[part 2 of 2: packages /Cluster to /Signal]
AUTOSAR XML (schema 00048)
package /Cluster  (continued)
  lin cluster LIN00: baudrate=19200, protocol-name=LIN, protocol-version=LIN21  # /*************************************************************************************/ // // Description: // Created: // Author: // Version: // Vehicle Project: // /*************************************************************************************/
    lin physical channel CHNL: comm-connectors=CN_LIN00
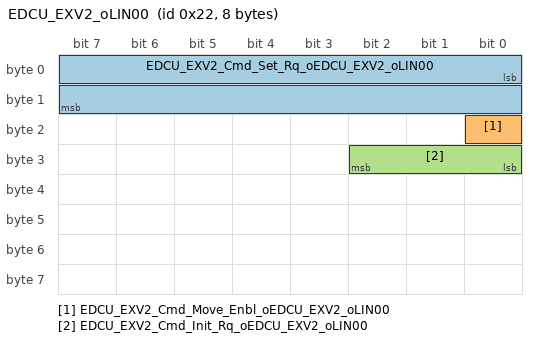
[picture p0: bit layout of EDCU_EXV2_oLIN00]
      frame EDCU_EXV2_oLIN00: id 0x22, from VCU, frame-length=8, lin-checksum=ENHANCED
        pdu EDCU_EXV2_oLIN00: length=8, unused-bit-pattern=255
          signal EDCU_EXV2_Cmd_Set_Rq_oEDCU_EXV2_oLIN00: start 0, 16 bit, little-endian, i-signal-type=PRIMITIVE, init-value=0, base-type=uint16, compu-method=CM_EDCU_EXV2_Cmd_Set_Rq, data-constr=DC_EDCU_EXV2_Cmd_Set_Rq
          signal EDCU_EXV2_Cmd_Move_Enbl_oEDCU_EXV2_oLIN00: start 16, 1 bit, little-endian, i-signal-type=PRIMITIVE, init-value=0, base-type=boolean, compu-method=CM_EDCU_EXV2_Cmd_Move_Enbl, data-constr=DC_EDCU_EXV2_Cmd_Move_Enbl
          signal EDCU_EXV2_Cmd_Init_Rq_oEDCU_EXV2_oLIN00: start 24, 3 bit, little-endian, i-signal-type=PRIMITIVE, init-value=0, base-type=uint8, compu-method=CM_EDCU_EXV2_Cmd_Init_Rq, data-constr=DC_EDCU_EXV2_Cmd_Init_Rq
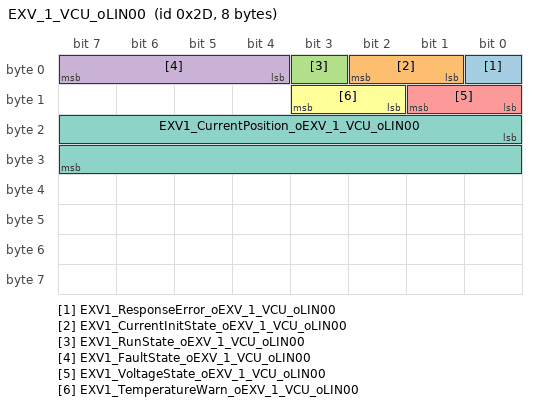
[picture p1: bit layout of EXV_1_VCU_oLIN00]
      frame EXV_1_VCU_oLIN00: id 0x2D, to VCU, frame-length=8, lin-checksum=ENHANCED
        pdu EXV_1_VCU_oLIN00: length=8, unused-bit-pattern=255
          signal EXV1_ResponseError_oEXV_1_VCU_oLIN00: start 0, 1 bit, little-endian, i-signal-type=PRIMITIVE, init-value=0, base-type=boolean, compu-method=CM_EXV1_ResponseError, data-constr=DC_EXV1_ResponseError, to VCU
          signal EXV1_CurrentInitState_oEXV_1_VCU_oLIN00: start 1, 2 bit, little-endian, i-signal-type=PRIMITIVE, init-value=0, base-type=uint8, compu-method=CM_EXV1_CurrentInitState, data-constr=DC_EXV1_CurrentInitState, to VCU
          signal EXV1_RunState_oEXV_1_VCU_oLIN00: start 3, 1 bit, little-endian, i-signal-type=PRIMITIVE, init-value=0, base-type=boolean, compu-method=CM_EXV1_RunState, data-constr=DC_EXV1_RunState, to VCU
          signal EXV1_FaultState_oEXV_1_VCU_oLIN00: start 4, 4 bit, little-endian, i-signal-type=PRIMITIVE, init-value=0, base-type=uint8, compu-method=CM_EXV1_FaultState, data-constr=DC_EXV1_FaultState, to VCU
          signal EXV1_VoltageState_oEXV_1_VCU_oLIN00: start 8, 2 bit, little-endian, i-signal-type=PRIMITIVE, init-value=0, base-type=uint8, compu-method=CM_EXV1_VoltageState, data-constr=DC_EXV1_VoltageState, to VCU
          signal EXV1_TemperatureWarn_oEXV_1_VCU_oLIN00: start 10, 2 bit, little-endian, i-signal-type=PRIMITIVE, init-value=0, base-type=uint8, compu-method=CM_EXV1_TemperatureWarn, data-constr=DC_EXV1_TemperatureWarn, to VCU
          signal EXV1_CurrentPosition_oEXV_1_VCU_oLIN00: start 16, 16 bit, little-endian, i-signal-type=PRIMITIVE, init-value=0, base-type=uint16, compu-method=CM_EXV1_CurrentPosition, data-constr=DC_EXV1_CurrentPosition, to VCU
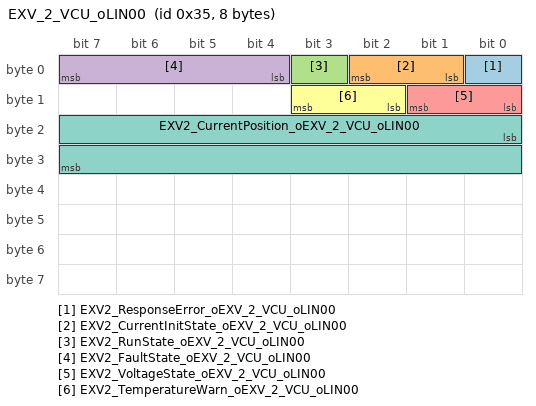
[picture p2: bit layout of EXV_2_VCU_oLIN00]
      frame EXV_2_VCU_oLIN00: id 0x35, to VCU, frame-length=8, lin-checksum=ENHANCED
        pdu EXV_2_VCU_oLIN00: length=8, unused-bit-pattern=255
          signal EXV2_ResponseError_oEXV_2_VCU_oLIN00: start 0, 1 bit, little-endian, i-signal-type=PRIMITIVE, init-value=0, base-type=boolean, compu-method=CM_EXV2_ResponseError, data-constr=DC_EXV2_ResponseError, to VCU
          signal EXV2_CurrentInitState_oEXV_2_VCU_oLIN00: start 1, 2 bit, little-endian, i-signal-type=PRIMITIVE, init-value=0, base-type=uint8, compu-method=CM_EXV2_CurrentInitState, data-constr=DC_EXV2_CurrentInitState, to VCU
          signal EXV2_RunState_oEXV_2_VCU_oLIN00: start 3, 1 bit, little-endian, i-signal-type=PRIMITIVE, init-value=0, base-type=boolean, compu-method=CM_EXV2_RunState, data-constr=DC_EXV2_RunState, to VCU
          signal EXV2_FaultState_oEXV_2_VCU_oLIN00: start 4, 4 bit, little-endian, i-signal-type=PRIMITIVE, init-value=0, base-type=uint8, compu-method=CM_EXV2_FaultState, data-constr=DC_EXV2_FaultState, to VCU
          signal EXV2_VoltageState_oEXV_2_VCU_oLIN00: start 8, 2 bit, little-endian, i-signal-type=PRIMITIVE, init-value=0, base-type=uint8, compu-method=CM_EXV2_VoltageState, data-constr=DC_EXV2_VoltageState, to VCU
          signal EXV2_TemperatureWarn_oEXV_2_VCU_oLIN00: start 10, 2 bit, little-endian, i-signal-type=PRIMITIVE, init-value=0, base-type=uint8, compu-method=CM_EXV2_TemperatureWarn, data-constr=DC_EXV2_TemperatureWarn, to VCU
          signal EXV2_CurrentPosition_oEXV_2_VCU_oLIN00: start 16, 16 bit, little-endian, i-signal-type=PRIMITIVE, init-value=0, base-type=uint16, compu-method=CM_EXV2_CurrentPosition, data-constr=DC_EXV2_CurrentPosition, to VCU
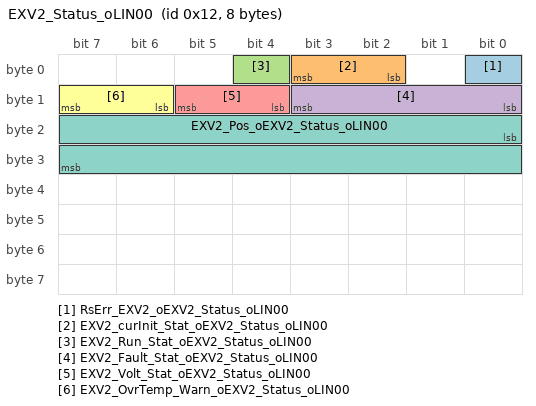
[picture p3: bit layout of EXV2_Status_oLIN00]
      frame EXV2_Status_oLIN00: id 0x12, to VCU, frame-length=8, lin-checksum=ENHANCED
        pdu EXV2_Status_oLIN00: length=8, unused-bit-pattern=255
          signal RsErr_EXV2_oEXV2_Status_oLIN00: start 0, 1 bit, little-endian, i-signal-type=PRIMITIVE, init-value=0, base-type=boolean, compu-method=CM_RsErr_EXV2, data-constr=DC_RsErr_EXV2, to VCU
          signal EXV2_curInit_Stat_oEXV2_Status_oLIN00: start 2, 2 bit, little-endian, i-signal-type=PRIMITIVE, init-value=0, base-type=uint8, compu-method=CM_EXV2_curInit_Stat, data-constr=DC_EXV2_curInit_Stat, to VCU
          signal EXV2_Run_Stat_oEXV2_Status_oLIN00: start 4, 1 bit, little-endian, i-signal-type=PRIMITIVE, init-value=0, base-type=boolean, compu-method=CM_EXV2_Run_Stat, data-constr=DC_EXV2_Run_Stat, to VCU
          signal EXV2_Fault_Stat_oEXV2_Status_oLIN00: start 8, 4 bit, little-endian, i-signal-type=PRIMITIVE, init-value=0, base-type=uint8, compu-method=CM_EXV2_Fault_Stat, data-constr=DC_EXV2_Fault_Stat, to VCU
          signal EXV2_Volt_Stat_oEXV2_Status_oLIN00: start 12, 2 bit, little-endian, i-signal-type=PRIMITIVE, init-value=0, base-type=uint8, compu-method=CM_EXV2_Volt_Stat, data-constr=DC_EXV2_Volt_Stat, to VCU
          signal EXV2_OvrTemp_Warn_oEXV2_Status_oLIN00: start 14, 2 bit, little-endian, i-signal-type=PRIMITIVE, init-value=0, base-type=uint8, compu-method=CM_EXV2_OvrTemp_Warn, data-constr=DC_EXV2_OvrTemp_Warn, to VCU
          signal EXV2_Pos_oEXV2_Status_oLIN00: start 16, 16 bit, little-endian, i-signal-type=PRIMITIVE, init-value=0, base-type=uint16, compu-method=CM_EXV2_Pos, data-constr=DC_EXV2_Pos, to VCU
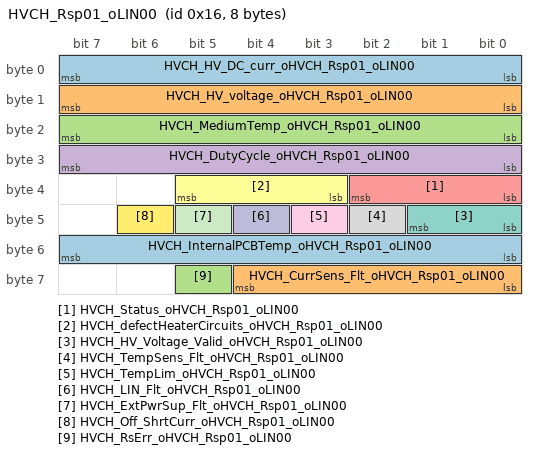
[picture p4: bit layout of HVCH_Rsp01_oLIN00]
      frame HVCH_Rsp01_oLIN00: id 0x16, to VCU, frame-length=8, lin-checksum=ENHANCED
        pdu HVCH_Rsp01_oLIN00: length=8, unused-bit-pattern=255
          signal HVCH_HV_DC_curr_oHVCH_Rsp01_oLIN00: start 0, 8 bit, little-endian, i-signal-type=PRIMITIVE, init-value=0, base-type=uint8, compu-method=CM_HVCH_HV_DC_curr, data-constr=DC_HVCH_HV_DC_curr, unit=U_A, to VCU
          signal HVCH_HV_voltage_oHVCH_Rsp01_oLIN00: start 8, 8 bit, little-endian, i-signal-type=PRIMITIVE, init-value=0, base-type=uint8, compu-method=CM_HVCH_HV_voltage, data-constr=DC_HVCH_HV_voltage, unit=U_V, to VCU
          signal HVCH_MediumTemp_oHVCH_Rsp01_oLIN00: start 16, 8 bit, little-endian, i-signal-type=PRIMITIVE, init-value=0, base-type=uint8, compu-method=CM_HVCH_MediumTemp, data-constr=DC_HVCH_MediumTemp, unit=U_celsius, to VCU
          signal HVCH_DutyCycle_oHVCH_Rsp01_oLIN00: start 24, 8 bit, little-endian, i-signal-type=PRIMITIVE, init-value=50, base-type=uint8, compu-method=CM_HVCH_DutyCycle, data-constr=DC_HVCH_DutyCycle, unit=U_percent, to VCU
          signal HVCH_Status_oHVCH_Rsp01_oLIN00: start 32, 3 bit, little-endian, i-signal-type=PRIMITIVE, init-value=0, base-type=uint8, compu-method=CM_HVCH_Status, data-constr=DC_HVCH_Status, to VCU
          signal HVCH_defectHeaterCircuits_oHVCH_Rsp01_oLIN00: start 35, 3 bit, little-endian, i-signal-type=PRIMITIVE, init-value=0, base-type=uint8, compu-method=CM_HVCH_defectHeaterCircuits, data-constr=DC_HVCH_defectHeaterCircuits, to VCU
          signal HVCH_HV_Voltage_Valid_oHVCH_Rsp01_oLIN00: start 40, 2 bit, little-endian, i-signal-type=PRIMITIVE, init-value=0, base-type=uint8, compu-method=CM_HVCH_HV_Voltage_Valid, data-constr=DC_HVCH_HV_Voltage_Valid, to VCU
          signal HVCH_TempSens_Flt_oHVCH_Rsp01_oLIN00: start 42, 1 bit, little-endian, i-signal-type=PRIMITIVE, init-value=0, base-type=boolean, compu-method=CM_HVCH_TempSens_Flt, data-constr=DC_HVCH_TempSens_Flt, to VCU
          signal HVCH_TempLim_oHVCH_Rsp01_oLIN00: start 43, 1 bit, little-endian, i-signal-type=PRIMITIVE, init-value=0, base-type=boolean, compu-method=CM_HVCH_TempLim, data-constr=DC_HVCH_TempLim, to VCU
          signal HVCH_LIN_Flt_oHVCH_Rsp01_oLIN00: start 44, 1 bit, little-endian, i-signal-type=PRIMITIVE, init-value=0, base-type=boolean, compu-method=CM_HVCH_LIN_Flt, data-constr=DC_HVCH_LIN_Flt, to VCU
          signal HVCH_ExtPwrSup_Flt_oHVCH_Rsp01_oLIN00: start 45, 1 bit, little-endian, i-signal-type=PRIMITIVE, init-value=0, base-type=boolean, compu-method=CM_HVCH_ExtPwrSup_Flt, data-constr=DC_HVCH_ExtPwrSup_Flt, to VCU
          signal HVCH_Off_ShrtCurr_oHVCH_Rsp01_oLIN00: start 46, 1 bit, little-endian, i-signal-type=PRIMITIVE, init-value=0, base-type=boolean, compu-method=CM_HVCH_Off_ShrtCurr, data-constr=DC_HVCH_Off_ShrtCurr, to VCU
          signal HVCH_InternalPCBTemp_oHVCH_Rsp01_oLIN00: start 48, 8 bit, little-endian, i-signal-type=PRIMITIVE, init-value=0, base-type=uint8, compu-method=CM_HVCH_InternalPCBTemp, data-constr=DC_HVCH_InternalPCBTemp, to VCU
          signal HVCH_CurrSens_Flt_oHVCH_Rsp01_oLIN00: start 56, 5 bit, little-endian, i-signal-type=PRIMITIVE, init-value=0, base-type=uint8, compu-method=CM_HVCH_CurrSens_Flt, data-constr=DC_HVCH_CurrSens_Flt, to VCU
          signal HVCH_RsErr_oHVCH_Rsp01_oLIN00: start 61, 1 bit, little-endian, i-signal-type=PRIMITIVE, init-value=0, base-type=boolean, compu-method=CM_HVCH_RsErr, data-constr=DC_HVCH_RsErr, to VCU
      frame HVCH_Rsp02_oLIN00: id 0x17, to VCU, frame-length=8, lin-checksum=ENHANCED
        pdu HVCH_Rsp02_oLIN00: length=8, unused-bit-pattern=255
          signal HVCH_IntelTemp_oHVCH_Rsp02_oLIN00: start 0, 8 bit, little-endian, i-signal-type=PRIMITIVE, init-value=0, base-type=uint8, compu-method=CM_HVCH_IntelTemp, data-constr=DC_HVCH_IntelTemp, unit=U_celsius, to VCU
      frame MasterReq_oLIN00: id 0x3C, from VCU, frame-length=8, lin-checksum=CLASSIC
        n pdu MasterReq_Tp_oLIN00: length=8
      frame PMP_Cmd_oLIN00: id 0x24, from VCU, frame-length=8, lin-checksum=ENHANCED
        pdu PMP_Cmd_oLIN00: length=8, unused-bit-pattern=255
          signal ECC_PMP2_SpdSet_oPMP_Cmd_oLIN00: start 8, 8 bit, little-endian, i-signal-type=PRIMITIVE, init-value=0, base-type=uint8, compu-method=CM_ECC_PMP2_SpdSet, data-constr=DC_ECC_PMP2_SpdSet, unit=U_p
          signal ECC_PMP3_SpdSet_oPMP_Cmd_oLIN00: start 16, 8 bit, little-endian, i-signal-type=PRIMITIVE, init-value=0, base-type=uint8, compu-method=CM_ECC_PMP3_SpdSet, data-constr=DC_ECC_PMP3_SpdSet, unit=U_p
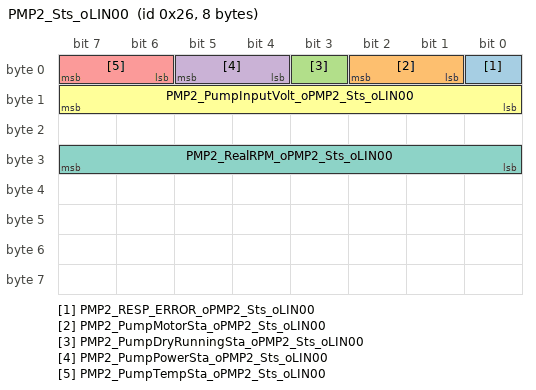
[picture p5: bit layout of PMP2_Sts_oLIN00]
      frame PMP2_Sts_oLIN00: id 0x26, to VCU, frame-length=8, lin-checksum=ENHANCED
        pdu PMP2_Sts_oLIN00: length=8, unused-bit-pattern=255
          signal PMP2_RESP_ERROR_oPMP2_Sts_oLIN00: start 0, 1 bit, little-endian, i-signal-type=PRIMITIVE, init-value=0, base-type=boolean, compu-method=CM_PMP2_RESP_ERROR, data-constr=DC_PMP2_RESP_ERROR, to VCU
          signal PMP2_PumpMotorSta_oPMP2_Sts_oLIN00: start 1, 2 bit, little-endian, i-signal-type=PRIMITIVE, init-value=0, base-type=uint8, compu-method=CM_PMP2_PumpMotorSta, data-constr=DC_PMP2_PumpMotorSta, to VCU
          signal PMP2_PumpDryRunningSta_oPMP2_Sts_oLIN00: start 3, 1 bit, little-endian, i-signal-type=PRIMITIVE, init-value=0, base-type=boolean, compu-method=CM_PMP2_PumpDryRunningSta, data-constr=DC_PMP2_PumpDryRunningSta, to VCU
          signal PMP2_PumpPowerSta_oPMP2_Sts_oLIN00: start 4, 2 bit, little-endian, i-signal-type=PRIMITIVE, init-value=0, base-type=uint8, compu-method=CM_PMP2_PumpPowerSta, data-constr=DC_PMP2_PumpPowerSta, to VCU
          signal PMP2_PumpTempSta_oPMP2_Sts_oLIN00: start 6, 2 bit, little-endian, i-signal-type=PRIMITIVE, init-value=0, base-type=uint8, compu-method=CM_PMP2_PumpTempSta, data-constr=DC_PMP2_PumpTempSta, to VCU
          signal PMP2_PumpInputVolt_oPMP2_Sts_oLIN00: start 8, 8 bit, little-endian, i-signal-type=PRIMITIVE, init-value=0, base-type=uint8, compu-method=CM_PMP2_PumpInputVolt, data-constr=DC_PMP2_PumpInputVolt, unit=U_V, to VCU
          signal PMP2_RealRPM_oPMP2_Sts_oLIN00: start 24, 8 bit, little-endian, i-signal-type=PRIMITIVE, init-value=0, base-type=uint8, compu-method=CM_PMP2_RealRPM, data-constr=DC_PMP2_RealRPM, unit=U_p, to VCU
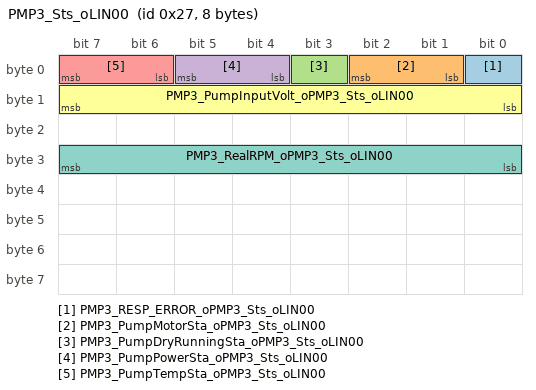
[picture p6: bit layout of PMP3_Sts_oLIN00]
      frame PMP3_Sts_oLIN00: id 0x27, to VCU, frame-length=8, lin-checksum=ENHANCED
        pdu PMP3_Sts_oLIN00: length=8, unused-bit-pattern=255
          signal PMP3_RESP_ERROR_oPMP3_Sts_oLIN00: start 0, 1 bit, little-endian, i-signal-type=PRIMITIVE, init-value=0, base-type=boolean, compu-method=CM_PMP3_RESP_ERROR, data-constr=DC_PMP3_RESP_ERROR, to VCU
          signal PMP3_PumpMotorSta_oPMP3_Sts_oLIN00: start 1, 2 bit, little-endian, i-signal-type=PRIMITIVE, init-value=0, base-type=uint8, compu-method=CM_PMP3_PumpMotorSta, data-constr=DC_PMP3_PumpMotorSta, to VCU
          signal PMP3_PumpDryRunningSta_oPMP3_Sts_oLIN00: start 3, 1 bit, little-endian, i-signal-type=PRIMITIVE, init-value=0, base-type=boolean, compu-method=CM_PMP3_PumpDryRunningSta, data-constr=DC_PMP3_PumpDryRunningSta, to VCU
          signal PMP3_PumpPowerSta_oPMP3_Sts_oLIN00: start 4, 2 bit, little-endian, i-signal-type=PRIMITIVE, init-value=0, base-type=uint8, compu-method=CM_PMP3_PumpPowerSta, data-constr=DC_PMP3_PumpPowerSta, to VCU
          signal PMP3_PumpTempSta_oPMP3_Sts_oLIN00: start 6, 2 bit, little-endian, i-signal-type=PRIMITIVE, init-value=0, base-type=uint8, compu-method=CM_PMP3_PumpTempSta, data-constr=DC_PMP3_PumpTempSta, to VCU
          signal PMP3_PumpInputVolt_oPMP3_Sts_oLIN00: start 8, 8 bit, little-endian, i-signal-type=PRIMITIVE, init-value=0, base-type=uint8, compu-method=CM_PMP3_PumpInputVolt, data-constr=DC_PMP3_PumpInputVolt, unit=U_V, to VCU
          signal PMP3_RealRPM_oPMP3_Sts_oLIN00: start 24, 8 bit, little-endian, i-signal-type=PRIMITIVE, init-value=0, base-type=uint8, compu-method=CM_PMP3_RealRPM, data-constr=DC_PMP3_RealRPM, unit=U_p, to VCU
      frame SlaveResp_oLIN00: id 0x3D, to VCU, frame-length=8, lin-checksum=CLASSIC
        n pdu SlaveResp_Tp_oLIN00: length=8
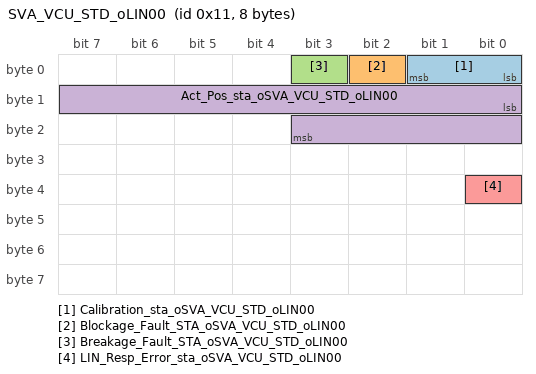
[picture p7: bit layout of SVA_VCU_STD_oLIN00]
      frame SVA_VCU_STD_oLIN00: id 0x11, to VCU, frame-length=8, lin-checksum=ENHANCED
        pdu SVA_VCU_STD_oLIN00: length=8, unused-bit-pattern=255
          signal Calibration_sta_oSVA_VCU_STD_oLIN00: start 0, 2 bit, little-endian, i-signal-type=PRIMITIVE, init-value=0, base-type=uint8, compu-method=CM_Calibration_sta, data-constr=DC_Calibration_sta, to VCU
          signal Blockage_Fault_STA_oSVA_VCU_STD_oLIN00: start 2, 1 bit, little-endian, i-signal-type=PRIMITIVE, init-value=0, base-type=boolean, compu-method=CM_Blockage_Fault_STA, data-constr=DC_Blockage_Fault_STA, to VCU
          signal Breakage_Fault_STA_oSVA_VCU_STD_oLIN00: start 3, 1 bit, little-endian, i-signal-type=PRIMITIVE, init-value=0, base-type=boolean, compu-method=CM_Breakage_Fault_STA, data-constr=DC_Breakage_Fault_STA, to VCU
          signal Act_Pos_sta_oSVA_VCU_STD_oLIN00: start 8, 12 bit, little-endian, i-signal-type=PRIMITIVE, init-value=0, base-type=uint16, compu-method=CM_Act_Pos_sta, data-constr=DC_Act_Pos_sta, unit=U_Degree, to VCU
          signal LIN_Resp_Error_sta_oSVA_VCU_STD_oLIN00: start 32, 1 bit, little-endian, i-signal-type=PRIMITIVE, init-value=0, base-type=boolean, compu-method=CM_LIN_Resp_Error_sta, data-constr=DC_LIN_Resp_Error_sta, to VCU
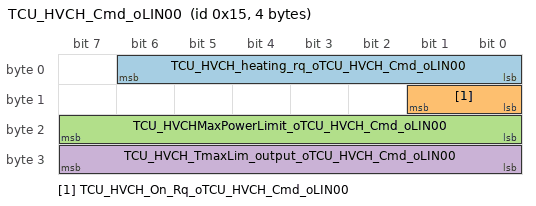
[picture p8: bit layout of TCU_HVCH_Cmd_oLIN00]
      frame TCU_HVCH_Cmd_oLIN00: id 0x15, from VCU, frame-length=4, lin-checksum=ENHANCED
        pdu TCU_HVCH_Cmd_oLIN00: length=4, unused-bit-pattern=255
          signal TCU_HVCH_heating_rq_oTCU_HVCH_Cmd_oLIN00: start 0, 7 bit, little-endian, i-signal-type=PRIMITIVE, init-value=0, base-type=uint8, compu-method=CM_TCU_HVCH_heating_rq, data-constr=DC_TCU_HVCH_heating_rq, unit=U_percent
          signal TCU_HVCH_On_Rq_oTCU_HVCH_Cmd_oLIN00: start 8, 2 bit, little-endian, i-signal-type=PRIMITIVE, init-value=0, base-type=uint8, invalid-value=3, compu-method=CM_TCU_HVCH_On_Rq, data-constr=DC_TCU_HVCH_On_Rq
          signal TCU_HVCHMaxPowerLimit_oTCU_HVCH_Cmd_oLIN00: start 16, 8 bit, little-endian, i-signal-type=PRIMITIVE, init-value=0, base-type=uint8, compu-method=CM_TCU_HVCHMaxPowerLimit, data-constr=DC_TCU_HVCHMaxPowerLimit, unit=U_KW
          signal TCU_HVCH_TmaxLim_output_oTCU_HVCH_Cmd_oLIN00: start 24, 8 bit, little-endian, i-signal-type=PRIMITIVE, init-value=0, base-type=uint8, compu-method=CM_TCU_HVCH_TmaxLim_output, data-constr=DC_TCU_HVCH_TmaxLim_output, unit=U_celsius
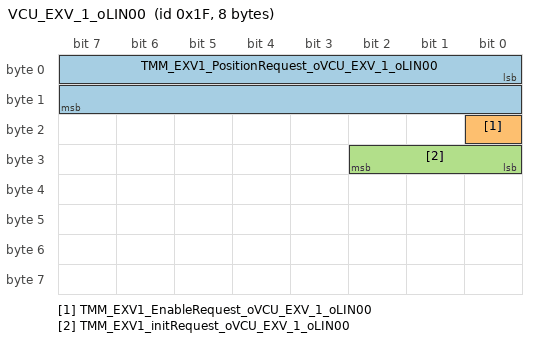
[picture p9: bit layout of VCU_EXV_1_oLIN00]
      frame VCU_EXV_1_oLIN00: id 0x1F, from VCU, frame-length=8, lin-checksum=ENHANCED
        pdu VCU_EXV_1_oLIN00: length=8, unused-bit-pattern=255
          signal TMM_EXV1_PositionRequest_oVCU_EXV_1_oLIN00: start 0, 16 bit, little-endian, i-signal-type=PRIMITIVE, init-value=0, base-type=uint16, compu-method=CM_TMM_EXV1_PositionRequest, data-constr=DC_TMM_EXV1_PositionRequest
          signal TMM_EXV1_EnableRequest_oVCU_EXV_1_oLIN00: start 16, 1 bit, little-endian, i-signal-type=PRIMITIVE, init-value=0, base-type=boolean, compu-method=CM_TMM_EXV1_EnableRequest, data-constr=DC_TMM_EXV1_EnableRequest
          signal TMM_EXV1_initRequest_oVCU_EXV_1_oLIN00: start 24, 3 bit, little-endian, i-signal-type=PRIMITIVE, init-value=0, base-type=uint8, compu-method=CM_TMM_EXV1_initRequest, data-constr=DC_TMM_EXV1_initRequest
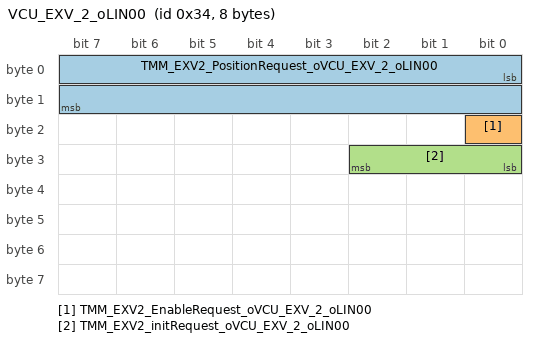
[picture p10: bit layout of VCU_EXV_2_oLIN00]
      frame VCU_EXV_2_oLIN00: id 0x34, from VCU, frame-length=8, lin-checksum=ENHANCED
        pdu VCU_EXV_2_oLIN00: length=8, unused-bit-pattern=255
          signal TMM_EXV2_PositionRequest_oVCU_EXV_2_oLIN00: start 0, 16 bit, little-endian, i-signal-type=PRIMITIVE, init-value=0, base-type=uint16, compu-method=CM_TMM_EXV2_PositionRequest, data-constr=DC_TMM_EXV2_PositionRequest
          signal TMM_EXV2_EnableRequest_oVCU_EXV_2_oLIN00: start 16, 1 bit, little-endian, i-signal-type=PRIMITIVE, init-value=0, base-type=boolean, compu-method=CM_TMM_EXV2_EnableRequest, data-constr=DC_TMM_EXV2_EnableRequest
          signal TMM_EXV2_initRequest_oVCU_EXV_2_oLIN00: start 24, 3 bit, little-endian, i-signal-type=PRIMITIVE, init-value=0, base-type=uint8, compu-method=CM_TMM_EXV2_initRequest, data-constr=DC_TMM_EXV2_initRequest
      frame VCU_SVA_CMD_oLIN00: id 0x10, from VCU, frame-length=8, lin-checksum=ENHANCED
        pdu VCU_SVA_CMD_oLIN00: length=8, unused-bit-pattern=255
          signal Calibration_cmd_oVCU_SVA_CMD_oLIN00: start 8, 1 bit, little-endian, i-signal-type=PRIMITIVE, init-value=0, base-type=boolean, compu-method=CM_Calibration_cmd, data-constr=DC_Calibration_cmd
          signal Target_Pos_cmd_oVCU_SVA_CMD_oLIN00: start 16, 12 bit, little-endian, i-signal-type=PRIMITIVE, init-value=0, base-type=uint16, compu-method=CM_Target_Pos_cmd, data-constr=DC_Target_Pos_cmd, unit=U_Degree
      pdu triggering PT_MasterReq: pdu=MasterReq_oLIN00, from VCU
      pdu triggering PT_MasterReq_ERV: pdu=MasterReq_ERV_oLIN00, from VCU
      pdu triggering PT_MasterReq_EXV_1: pdu=MasterReq_EXV_1_oLIN00, from VCU
      pdu triggering PT_MasterReq_EXV_2: pdu=MasterReq_EXV_2_oLIN00, from VCU
      pdu triggering PT_MasterReq_HVCH: pdu=MasterReq_HVCH_oLIN00, from VCU
      pdu triggering PT_MasterReq_PMP_1: pdu=MasterReq_PMP_1_oLIN00, from VCU
      pdu triggering PT_MasterReq_PMP_2: pdu=MasterReq_PMP_2_oLIN00, from VCU
      pdu triggering PT_MasterReq_SVA: pdu=MasterReq_SVA_oLIN00, from VCU
      pdu triggering PT_SlaveResp_ERV: pdu=SlaveResp_ERV_oLIN00, to VCU
      pdu triggering PT_SlaveResp_EXV_1: pdu=SlaveResp_EXV_1_oLIN00, to VCU
      pdu triggering PT_SlaveResp_EXV_2: pdu=SlaveResp_EXV_2_oLIN00, to VCU
      pdu triggering PT_SlaveResp_HVCH: pdu=SlaveResp_HVCH_oLIN00, to VCU
      pdu triggering PT_SlaveResp_PMP_1: pdu=SlaveResp_PMP_1_oLIN00, to VCU
      pdu triggering PT_SlaveResp_PMP_2: pdu=SlaveResp_PMP_2_oLIN00, to VCU
      pdu triggering PT_SlaveResp_SVA: pdu=SlaveResp_SVA_oLIN00, to VCU
      lin schedule table TCU_LIN_Schedule: run-mode=RUN-CONTINUOUS
        table-entrys:
          delay=0.01, position-in-table=0, frame-triggering=FT_EDCU_EXV2
          delay=0.01, position-in-table=1, frame-triggering=FT_EXV2_Status
          delay=0.1, position-in-table=2, frame-triggering=FT_VCU_EXV_1
          delay=0.1, position-in-table=3, frame-triggering=FT_EXV_1_VCU
          delay=0.1, position-in-table=4, frame-triggering=FT_VCU_EXV_2
          delay=0.1, position-in-table=5, frame-triggering=FT_EXV_2_VCU
          delay=0.01, position-in-table=6, frame-triggering=FT_PMP_Cmd
          delay=0.01, position-in-table=7, frame-triggering=FT_PMP2_Sts
          delay=0.01, position-in-table=8, frame-triggering=FT_PMP3_Sts
          delay=0.015, position-in-table=9, frame-triggering=FT_VCU_SVA_CMD
          delay=0.015, position-in-table=10, frame-triggering=FT_SVA_VCU_STD
          delay=0.02, position-in-table=11, frame-triggering=FT_TCU_HVCH_Cmd
          delay=0.02, position-in-table=12, frame-triggering=FT_HVCH_Rsp01
          delay=0.02, position-in-table=13, frame-triggering=FT_HVCH_Rsp02
  lin cluster LIN01: baudrate=19200, protocol-name=LIN, protocol-version=LIN21  # LIN4 | /*************************************************************************************/ // // Description: // Created: // Author: // Version: // Vehicle Project: // /*************************************************************************************/
    lin physical channel CHNL: comm-connectors=CN_LIN01
      frame MasterReq_oLIN01: id 0x3C, from VCU, frame-length=8, lin-checksum=CLASSIC
        n pdu MasterReq_Tp_oLIN01: length=8
      frame SlaveResp_oLIN01: id 0x3D, to VCU, frame-length=8, lin-checksum=CLASSIC
        n pdu SlaveResp_Tp_oLIN01: length=8
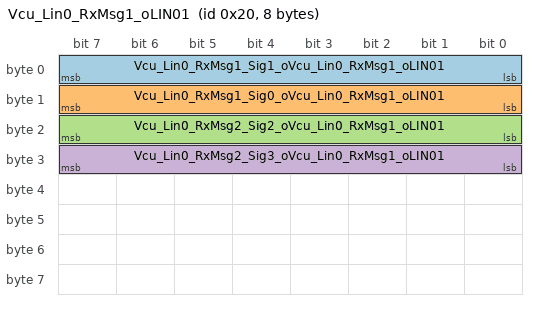
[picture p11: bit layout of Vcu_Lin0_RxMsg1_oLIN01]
      frame Vcu_Lin0_RxMsg1_oLIN01: id 0x20, to VCU, frame-length=8, lin-checksum=ENHANCED
        pdu Vcu_Lin0_RxMsg1_oLIN01: length=8, unused-bit-pattern=255
          signal Vcu_Lin0_RxMsg1_Sig1_oVcu_Lin0_RxMsg1_oLIN01: start 0, 8 bit, little-endian, i-signal-type=PRIMITIVE, init-value=0, base-type=uint8, compu-method=CM_Vcu_Lin0_RxMsg1_Sig1, data-constr=DC_Vcu_Lin0_RxMsg1_Sig1, to VCU
          signal Vcu_Lin0_RxMsg1_Sig0_oVcu_Lin0_RxMsg1_oLIN01: start 8, 8 bit, little-endian, i-signal-type=PRIMITIVE, init-value=0, base-type=uint8, compu-method=CM_Vcu_Lin0_RxMsg1_Sig0, data-constr=DC_Vcu_Lin0_RxMsg1_Sig0, to VCU
          signal Vcu_Lin0_RxMsg2_Sig2_oVcu_Lin0_RxMsg1_oLIN01: start 16, 8 bit, little-endian, i-signal-type=PRIMITIVE, init-value=0, base-type=uint8, compu-method=CM_Vcu_Lin0_RxMsg2_Sig2, data-constr=DC_Vcu_Lin0_RxMsg2_Sig2, to VCU
          signal Vcu_Lin0_RxMsg2_Sig3_oVcu_Lin0_RxMsg1_oLIN01: start 24, 8 bit, little-endian, i-signal-type=PRIMITIVE, init-value=0, base-type=uint8, compu-method=CM_Vcu_Lin0_RxMsg2_Sig3, data-constr=DC_Vcu_Lin0_RxMsg2_Sig3, to VCU
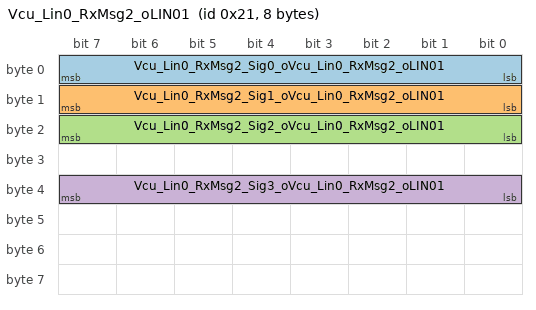
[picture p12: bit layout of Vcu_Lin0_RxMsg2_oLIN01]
      frame Vcu_Lin0_RxMsg2_oLIN01: id 0x21, to VCU, frame-length=8, lin-checksum=ENHANCED
        pdu Vcu_Lin0_RxMsg2_oLIN01: length=8, unused-bit-pattern=255
          signal Vcu_Lin0_RxMsg2_Sig0_oVcu_Lin0_RxMsg2_oLIN01: start 0, 8 bit, little-endian, i-signal-type=PRIMITIVE, init-value=0, base-type=uint8, compu-method=CM_Vcu_Lin0_RxMsg2_Sig0, data-constr=DC_Vcu_Lin0_RxMsg2_Sig0, to VCU
          signal Vcu_Lin0_RxMsg2_Sig1_oVcu_Lin0_RxMsg2_oLIN01: start 8, 8 bit, little-endian, i-signal-type=PRIMITIVE, init-value=0, base-type=uint8, compu-method=CM_Vcu_Lin0_RxMsg2_Sig1, data-constr=DC_Vcu_Lin0_RxMsg2_Sig1, to VCU
          signal Vcu_Lin0_RxMsg2_Sig2_oVcu_Lin0_RxMsg2_oLIN01: start 16, 8 bit, little-endian, i-signal-type=PRIMITIVE, init-value=0, base-type=uint8, compu-method=CM_Vcu_Lin0_RxMsg2_Sig2, data-constr=DC_Vcu_Lin0_RxMsg2_Sig2, to VCU
          signal Vcu_Lin0_RxMsg2_Sig3_oVcu_Lin0_RxMsg2_oLIN01: start 32, 8 bit, little-endian, i-signal-type=PRIMITIVE, init-value=0, base-type=uint8, compu-method=CM_Vcu_Lin0_RxMsg2_Sig3, data-constr=DC_Vcu_Lin0_RxMsg2_Sig3, to VCU
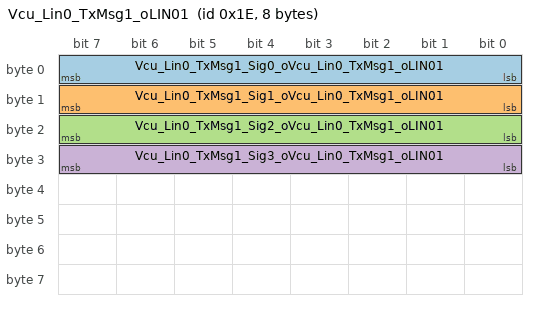
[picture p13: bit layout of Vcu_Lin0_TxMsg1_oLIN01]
      frame Vcu_Lin0_TxMsg1_oLIN01: id 0x1E, from VCU, frame-length=8, lin-checksum=ENHANCED
        pdu Vcu_Lin0_TxMsg1_oLIN01: length=8, unused-bit-pattern=255
          signal Vcu_Lin0_TxMsg1_Sig0_oVcu_Lin0_TxMsg1_oLIN01: start 0, 8 bit, little-endian, i-signal-type=PRIMITIVE, init-value=0, base-type=uint8, compu-method=CM_Vcu_Lin0_TxMsg1_Sig0, data-constr=DC_Vcu_Lin0_TxMsg1_Sig0
          signal Vcu_Lin0_TxMsg1_Sig1_oVcu_Lin0_TxMsg1_oLIN01: start 8, 8 bit, little-endian, i-signal-type=PRIMITIVE, init-value=0, base-type=uint8, compu-method=CM_Vcu_Lin0_TxMsg1_Sig1, data-constr=DC_Vcu_Lin0_TxMsg1_Sig1
          signal Vcu_Lin0_TxMsg1_Sig2_oVcu_Lin0_TxMsg1_oLIN01: start 16, 8 bit, little-endian, i-signal-type=PRIMITIVE, init-value=0, base-type=uint8, compu-method=CM_Vcu_Lin0_TxMsg1_Sig2, data-constr=DC_Vcu_Lin0_TxMsg1_Sig2
          signal Vcu_Lin0_TxMsg1_Sig3_oVcu_Lin0_TxMsg1_oLIN01: start 24, 8 bit, little-endian, i-signal-type=PRIMITIVE, init-value=0, base-type=uint8, compu-method=CM_Vcu_Lin0_TxMsg1_Sig3, data-constr=DC_Vcu_Lin0_TxMsg1_Sig3
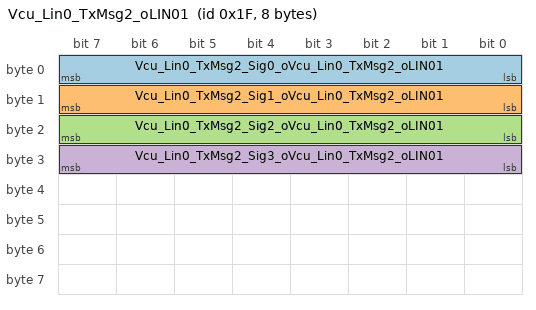
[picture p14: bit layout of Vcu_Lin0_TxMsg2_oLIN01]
      frame Vcu_Lin0_TxMsg2_oLIN01: id 0x1F, from VCU, frame-length=8, lin-checksum=ENHANCED
        pdu Vcu_Lin0_TxMsg2_oLIN01: length=8, unused-bit-pattern=255
          signal Vcu_Lin0_TxMsg2_Sig0_oVcu_Lin0_TxMsg2_oLIN01: start 0, 8 bit, little-endian, i-signal-type=PRIMITIVE, init-value=0, base-type=uint8, compu-method=CM_Vcu_Lin0_TxMsg2_Sig0, data-constr=DC_Vcu_Lin0_TxMsg2_Sig0
          signal Vcu_Lin0_TxMsg2_Sig1_oVcu_Lin0_TxMsg2_oLIN01: start 8, 8 bit, little-endian, i-signal-type=PRIMITIVE, init-value=0, base-type=uint8, compu-method=CM_Vcu_Lin0_TxMsg2_Sig1, data-constr=DC_Vcu_Lin0_TxMsg2_Sig1
          signal Vcu_Lin0_TxMsg2_Sig2_oVcu_Lin0_TxMsg2_oLIN01: start 16, 8 bit, little-endian, i-signal-type=PRIMITIVE, init-value=0, base-type=uint8, compu-method=CM_Vcu_Lin0_TxMsg2_Sig2, data-constr=DC_Vcu_Lin0_TxMsg2_Sig2
          signal Vcu_Lin0_TxMsg2_Sig3_oVcu_Lin0_TxMsg2_oLIN01: start 24, 8 bit, little-endian, i-signal-type=PRIMITIVE, init-value=0, base-type=uint8, compu-method=CM_Vcu_Lin0_TxMsg2_Sig3, data-constr=DC_Vcu_Lin0_TxMsg2_Sig3
      pdu triggering PT_MasterReq: pdu=MasterReq_oLIN01, from VCU
      pdu triggering PT_MasterReq_GWM: pdu=MasterReq_GWM_oLIN01, from VCU
      pdu triggering PT_SlaveResp_GWM: pdu=SlaveResp_GWM_oLIN01, to VCU
      lin schedule table Vcu_Lin0_Schedule: run-mode=RUN-CONTINUOUS
        table-entrys:
          delay=0.02, position-in-table=0, frame-triggering=FT_Vcu_Lin0_TxMsg1
          delay=0.02, position-in-table=1, frame-triggering=FT_Vcu_Lin0_TxMsg2
          delay=0.02, position-in-table=2, frame-triggering=FT_Vcu_Lin0_RxMsg1
          delay=0.02, position-in-table=3, frame-triggering=FT_Vcu_Lin0_RxMsg2
  lin cluster LIN02: baudrate=19200, protocol-name=LIN, protocol-version=LIN21  # LIN3 | /*************************************************************************************/ // // Description: // Created: // Author: // Version: // Vehicle Project: // /*************************************************************************************/
    lin physical channel CHNL: comm-connectors=CN_LIN02
      frame MasterReq_oLIN02: id 0x3C, from VCU, frame-length=8, lin-checksum=CLASSIC
        n pdu MasterReq_Tp_oLIN02: length=8
      frame SlaveResp_oLIN02: id 0x3D, to VCU, frame-length=8, lin-checksum=CLASSIC
        n pdu SlaveResp_Tp_oLIN02: length=8
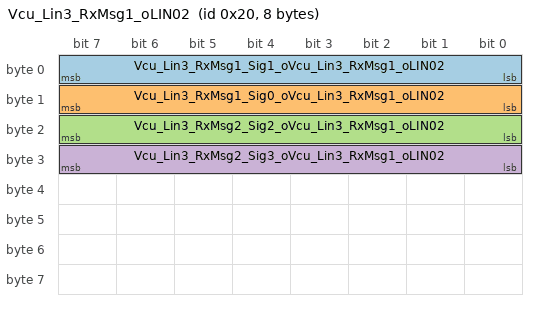
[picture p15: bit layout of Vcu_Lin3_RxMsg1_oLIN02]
      frame Vcu_Lin3_RxMsg1_oLIN02: id 0x20, to VCU, frame-length=8, lin-checksum=ENHANCED
        pdu Vcu_Lin3_RxMsg1_oLIN02: length=8, unused-bit-pattern=255
          signal Vcu_Lin3_RxMsg1_Sig1_oVcu_Lin3_RxMsg1_oLIN02: start 0, 8 bit, little-endian, i-signal-type=PRIMITIVE, init-value=0, base-type=uint8, compu-method=CM_Vcu_Lin3_RxMsg1_Sig1, data-constr=DC_Vcu_Lin3_RxMsg1_Sig1, to VCU
          signal Vcu_Lin3_RxMsg1_Sig0_oVcu_Lin3_RxMsg1_oLIN02: start 8, 8 bit, little-endian, i-signal-type=PRIMITIVE, init-value=0, base-type=uint8, compu-method=CM_Vcu_Lin3_RxMsg1_Sig0, data-constr=DC_Vcu_Lin3_RxMsg1_Sig0, to VCU
          signal Vcu_Lin3_RxMsg2_Sig2_oVcu_Lin3_RxMsg1_oLIN02: start 16, 8 bit, little-endian, i-signal-type=PRIMITIVE, init-value=0, base-type=uint8, compu-method=CM_Vcu_Lin3_RxMsg2_Sig2, data-constr=DC_Vcu_Lin3_RxMsg2_Sig2, to VCU
          signal Vcu_Lin3_RxMsg2_Sig3_oVcu_Lin3_RxMsg1_oLIN02: start 24, 8 bit, little-endian, i-signal-type=PRIMITIVE, init-value=0, base-type=uint8, compu-method=CM_Vcu_Lin3_RxMsg2_Sig3, data-constr=DC_Vcu_Lin3_RxMsg2_Sig3, to VCU
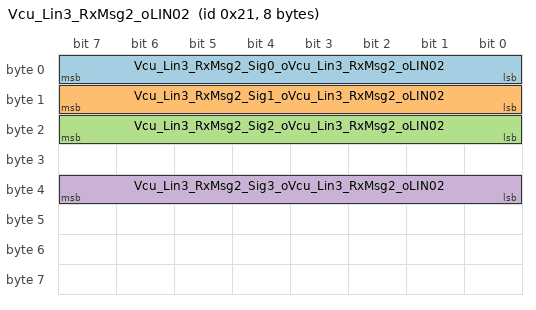
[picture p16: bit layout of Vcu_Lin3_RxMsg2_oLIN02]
      frame Vcu_Lin3_RxMsg2_oLIN02: id 0x21, to VCU, frame-length=8, lin-checksum=ENHANCED
        pdu Vcu_Lin3_RxMsg2_oLIN02: length=8, unused-bit-pattern=255
          signal Vcu_Lin3_RxMsg2_Sig0_oVcu_Lin3_RxMsg2_oLIN02: start 0, 8 bit, little-endian, i-signal-type=PRIMITIVE, init-value=0, base-type=uint8, compu-method=CM_Vcu_Lin3_RxMsg2_Sig0, data-constr=DC_Vcu_Lin3_RxMsg2_Sig0, to VCU
          signal Vcu_Lin3_RxMsg2_Sig1_oVcu_Lin3_RxMsg2_oLIN02: start 8, 8 bit, little-endian, i-signal-type=PRIMITIVE, init-value=0, base-type=uint8, compu-method=CM_Vcu_Lin3_RxMsg2_Sig1, data-constr=DC_Vcu_Lin3_RxMsg2_Sig1, to VCU
          signal Vcu_Lin3_RxMsg2_Sig2_oVcu_Lin3_RxMsg2_oLIN02: start 16, 8 bit, little-endian, i-signal-type=PRIMITIVE, init-value=0, base-type=uint8, compu-method=CM_Vcu_Lin3_RxMsg2_Sig2, data-constr=DC_Vcu_Lin3_RxMsg2_Sig2, to VCU
          signal Vcu_Lin3_RxMsg2_Sig3_oVcu_Lin3_RxMsg2_oLIN02: start 32, 8 bit, little-endian, i-signal-type=PRIMITIVE, init-value=0, base-type=uint8, compu-method=CM_Vcu_Lin3_RxMsg2_Sig3, data-constr=DC_Vcu_Lin3_RxMsg2_Sig3, to VCU
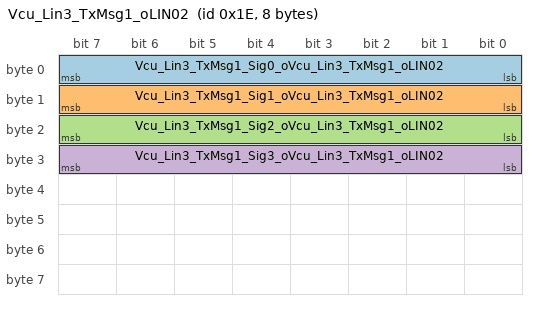
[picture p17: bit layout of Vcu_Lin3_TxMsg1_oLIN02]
      frame Vcu_Lin3_TxMsg1_oLIN02: id 0x1E, from VCU, frame-length=8, lin-checksum=ENHANCED
        pdu Vcu_Lin3_TxMsg1_oLIN02: length=8, unused-bit-pattern=255
          signal Vcu_Lin3_TxMsg1_Sig0_oVcu_Lin3_TxMsg1_oLIN02: start 0, 8 bit, little-endian, i-signal-type=PRIMITIVE, init-value=0, base-type=uint8, compu-method=CM_Vcu_Lin3_TxMsg1_Sig0, data-constr=DC_Vcu_Lin3_TxMsg1_Sig0
          signal Vcu_Lin3_TxMsg1_Sig1_oVcu_Lin3_TxMsg1_oLIN02: start 8, 8 bit, little-endian, i-signal-type=PRIMITIVE, init-value=0, base-type=uint8, compu-method=CM_Vcu_Lin3_TxMsg1_Sig1, data-constr=DC_Vcu_Lin3_TxMsg1_Sig1
          signal Vcu_Lin3_TxMsg1_Sig2_oVcu_Lin3_TxMsg1_oLIN02: start 16, 8 bit, little-endian, i-signal-type=PRIMITIVE, init-value=0, base-type=uint8, compu-method=CM_Vcu_Lin3_TxMsg1_Sig2, data-constr=DC_Vcu_Lin3_TxMsg1_Sig2
          signal Vcu_Lin3_TxMsg1_Sig3_oVcu_Lin3_TxMsg1_oLIN02: start 24, 8 bit, little-endian, i-signal-type=PRIMITIVE, init-value=0, base-type=uint8, compu-method=CM_Vcu_Lin3_TxMsg1_Sig3, data-constr=DC_Vcu_Lin3_TxMsg1_Sig3
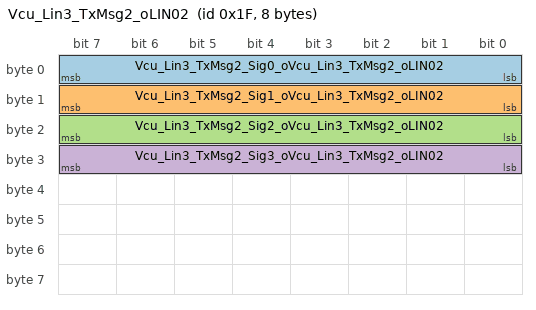
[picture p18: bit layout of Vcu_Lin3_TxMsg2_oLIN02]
      frame Vcu_Lin3_TxMsg2_oLIN02: id 0x1F, from VCU, frame-length=8, lin-checksum=ENHANCED
        pdu Vcu_Lin3_TxMsg2_oLIN02: length=8, unused-bit-pattern=255
          signal Vcu_Lin3_TxMsg2_Sig0_oVcu_Lin3_TxMsg2_oLIN02: start 0, 8 bit, little-endian, i-signal-type=PRIMITIVE, init-value=0, base-type=uint8, compu-method=CM_Vcu_Lin3_TxMsg2_Sig0, data-constr=DC_Vcu_Lin3_TxMsg2_Sig0
          signal Vcu_Lin3_TxMsg2_Sig1_oVcu_Lin3_TxMsg2_oLIN02: start 8, 8 bit, little-endian, i-signal-type=PRIMITIVE, init-value=0, base-type=uint8, compu-method=CM_Vcu_Lin3_TxMsg2_Sig1, data-constr=DC_Vcu_Lin3_TxMsg2_Sig1
          signal Vcu_Lin3_TxMsg2_Sig2_oVcu_Lin3_TxMsg2_oLIN02: start 16, 8 bit, little-endian, i-signal-type=PRIMITIVE, init-value=0, base-type=uint8, compu-method=CM_Vcu_Lin3_TxMsg2_Sig2, data-constr=DC_Vcu_Lin3_TxMsg2_Sig2
          signal Vcu_Lin3_TxMsg2_Sig3_oVcu_Lin3_TxMsg2_oLIN02: start 24, 8 bit, little-endian, i-signal-type=PRIMITIVE, init-value=0, base-type=uint8, compu-method=CM_Vcu_Lin3_TxMsg2_Sig3, data-constr=DC_Vcu_Lin3_TxMsg2_Sig3
      pdu triggering PT_MasterReq: pdu=MasterReq_oLIN02, from VCU
      pdu triggering PT_MasterReq_GWM: pdu=MasterReq_GWM_oLIN02, from VCU
      pdu triggering PT_SlaveResp_GWM: pdu=SlaveResp_GWM_oLIN02, to VCU
      lin schedule table Vcu_Lin3_Schedule: run-mode=RUN-CONTINUOUS
        table-entrys:
          delay=0.02, position-in-table=0, frame-triggering=FT_Vcu_Lin3_TxMsg1
          delay=0.02, position-in-table=1, frame-triggering=FT_Vcu_Lin3_TxMsg2
          delay=0.02, position-in-table=2, frame-triggering=FT_Vcu_Lin3_RxMsg1
          delay=0.02, position-in-table=3, frame-triggering=FT_Vcu_Lin3_RxMsg2
package /ECU
  ecu instance VCU: associated-com-i-pdu-group=[VCU_oATOM_CANFD_Matrix_CH_V600_202502_Rx, VCU_oATOM_CANFD_Matrix_CH_V600_202502_Tx, VCU_oLIN00_Rx, VCU_oLIN00_Tx, VCU_oLIN01_Rx, VCU_oLIN01_Tx, VCU_oLIN02_Rx, VCU_oLIN02_Tx, VCU_oTC37X_VCU_CAN00_Rx, VCU_oTC37X_VCU_CAN00_Tx, VCU_oTC37X_VCU_CAN01_Rx, VCU_oTC37X_VCU_CAN01_Tx, VCU_oTC37X_VCU_CAN03_Rx, VCU_oTC37X_VCU_CAN03_Tx, VCU_oTC37X_VCU_CAN12_Rx, VCU_oTC37X_VCU_CAN12_Tx]
    5 x can communication controller:
      CT_ATOM_CANFD_Matrix_CH_V600_202502
      CT_TC37X_VCU_CAN00
      CT_TC37X_VCU_CAN01
      CT_TC37X_VCU_CAN03
      CT_TC37X_VCU_CAN12
    lin master CT_LIN{00..02}: protocol-version=LIN21, time-base=0.005, time-base-jitter=0.0001
    can communication connector CN_ATOM_CANFD_Matrix_CH_V600_202502: comm-controller=CT_ATOM_CANFD_Matrix_CH_V600_202502
    can communication connector CN_TC37X_VCU_CAN00: comm-controller=CT_TC37X_VCU_CAN00
    can communication connector CN_TC37X_VCU_CAN01: comm-controller=CT_TC37X_VCU_CAN01
    can communication connector CN_TC37X_VCU_CAN03: comm-controller=CT_TC37X_VCU_CAN03
    can communication connector CN_TC37X_VCU_CAN12: comm-controller=CT_TC37X_VCU_CAN12
    lin communication connector CN_LIN{00..02}: comm-controller=CT_LIN{00..02}
package /Gateway
  gateway VCU: ecu=VCU
package /IPDUGroup
  16 x i signal i pdu group:
    VCU_oATOM_CANFD_Matrix_CH_V600_202502_Rx: communication-direction=IN
      i-signal-i-pdus:
        ACU_01_oATOM_CANFD_Matrix_CH_V600_202502
        ACU_02_oATOM_CANFD_Matrix_CH_V600_202502
        ACU_info_oATOM_CANFD_Matrix_CH_V600_202502
        ADCU_ACC_02_oATOM_CANFD_Matrix_CH_V600_202502
        ADCU_AEB_01_oATOM_CANFD_Matrix_CH_V600_202502
        ADCU_APS_01_oATOM_CANFD_Matrix_CH_V600_202502
        ADCU_APS_02_oATOM_CANFD_Matrix_CH_V600_202502
        ADCU_DA_oATOM_CANFD_Matrix_CH_V600_202502
        IBS_ACC_oATOM_CANFD_Matrix_CH_V600_202502
        IBS_APS_oATOM_CANFD_Matrix_CH_V600_202502
        IBS_Status_{01..04}_oATOM_CANFD_Matrix_CH_V600_202502
        IBS_Status_06_oATOM_CANFD_Matrix_CH_V600_202502
        IBS_Torque_oATOM_CANFD_Matrix_CH_V600_202502
        IBS_VCU_MotorControl_oATOM_CANFD_Matrix_CH_V600_202502
        IBS_WheelSpeed_01_oATOM_CANFD_Matrix_CH_V600_202502
        IBS_WheelSpeed_02_oATOM_CANFD_Matrix_CH_V600_202502
        SGW_17_oATOM_CANFD_Matrix_CH_V600_202502
    VCU_oATOM_CANFD_Matrix_CH_V600_202502_Tx: communication-direction=OUT
      i-signal-i-pdus:
        VCU_{02..04}_oATOM_CANFD_Matrix_CH_V600_202502
        VCU_AccPedal_oATOM_CANFD_Matrix_CH_V600_202502
        VCU_BMS_oATOM_CANFD_Matrix_CH_V600_202502
        VCU_Chassis_01_oATOM_CANFD_Matrix_CH_V600_202502
        VCU_HMIsignals_01_oATOM_CANFD_Matrix_CH_V600_202502
        VCU_HMIsignals_02_oATOM_CANFD_Matrix_CH_V600_202502
        VCU_IBS_01_oATOM_CANFD_Matrix_CH_V600_202502
        VCU_MCU_03_oATOM_CANFD_Matrix_CH_V600_202502
        VCU_PlugInChrgInfo_oATOM_CANFD_Matrix_CH_V600_202502
    VCU_oLIN00_Rx: communication-direction=IN
      i-signal-i-pdus:
        EXV_1_VCU_oLIN00
        EXV_2_VCU_oLIN00
        EXV2_Status_oLIN00
        HVCH_Rsp01_oLIN00
        HVCH_Rsp02_oLIN00
        PMP2_Sts_oLIN00
        PMP3_Sts_oLIN00
        SVA_VCU_STD_oLIN00
    VCU_oLIN00_Tx: communication-direction=OUT, i-signal-i-pdus=[EDCU_EXV2_oLIN00, PMP_Cmd_oLIN00, TCU_HVCH_Cmd_oLIN00, VCU_EXV_1_oLIN00, VCU_EXV_2_oLIN00, VCU_SVA_CMD_oLIN00]
    VCU_oLIN01_Rx: communication-direction=IN, i-signal-i-pdus=[Vcu_Lin0_RxMsg1_oLIN01, Vcu_Lin0_RxMsg2_oLIN01]
    VCU_oLIN01_Tx: communication-direction=OUT, i-signal-i-pdus=[Vcu_Lin0_TxMsg1_oLIN01, Vcu_Lin0_TxMsg2_oLIN01]
    VCU_oLIN02_Rx: communication-direction=IN, i-signal-i-pdus=[Vcu_Lin3_RxMsg1_oLIN02, Vcu_Lin3_RxMsg2_oLIN02]
    VCU_oLIN02_Tx: communication-direction=OUT, i-signal-i-pdus=[Vcu_Lin3_TxMsg1_oLIN02, Vcu_Lin3_TxMsg2_oLIN02]
    VCU_oTC37X_VCU_CAN00_Rx: communication-direction=IN, i-signal-i-pdus=[VcuRxMsg1_oTC37X_VCU_CAN00, VcuRxMsg2_oTC37X_VCU_CAN00]
    VCU_oTC37X_VCU_CAN00_Tx: communication-direction=OUT
      i-signal-i-pdus:
        VcuTxIoMsg{1..8}_oTC37X_VCU_CAN00
        VcuTxMsg1_oTC37X_VCU_CAN00
        VcuTxMsg2_oTC37X_VCU_CAN00
    VCU_oTC37X_VCU_CAN01_Rx: communication-direction=IN
      i-signal-i-pdus:
        VcuRxCtrlMsg{0..2}_oTC37X_VCU_CAN01
        VcuRxMsg3_oTC37X_VCU_CAN01
        VcuRxMsg4_oTC37X_VCU_CAN01
    VCU_oTC37X_VCU_CAN01_Tx: communication-direction=OUT
      i-signal-i-pdus:
        VcuAdcTxG0Msg0_oTC37X_VCU_CAN01
        VcuAdcTxG0Msg1_oTC37X_VCU_CAN01
        VcuAdcTxG1Msg0_oTC37X_VCU_CAN01
        VcuAdcTxG1Msg1_oTC37X_VCU_CAN01
        VcuAdcTxG2Msg0_oTC37X_VCU_CAN01
        VcuAdcTxG2Msg1_oTC37X_VCU_CAN01
        VcuAdcTxG3Msg0_oTC37X_VCU_CAN01
        VcuAdcTxG3Msg1_oTC37X_VCU_CAN01
        VcuAdcTxG8Msg{0..3}_oTC37X_VCU_CAN01
        VcuMeasurementMsg0_oTC37X_VCU_CAN01
    VCU_oTC37X_VCU_CAN03_Rx: communication-direction=IN, i-signal-i-pdus=[VcuCan03RxMsg1_oTC37X_VCU_CAN03, VcuCan03RxMsg2_oTC37X_VCU_CAN03]
    VCU_oTC37X_VCU_CAN03_Tx: communication-direction=OUT, i-signal-i-pdus=[VcuCan03TxMsg1_oTC37X_VCU_CAN03, VcuCan03TxMsg2_oTC37X_VCU_CAN03]
    VCU_oTC37X_VCU_CAN12_Rx: communication-direction=IN, i-signal-i-pdus=[VcuCan12RxMsg3_oTC37X_VCU_CAN12, VcuCan12RxMsg4_oTC37X_VCU_CAN12]
    VCU_oTC37X_VCU_CAN12_Tx: communication-direction=OUT, i-signal-i-pdus=[VcuCan12TxMsg1_oTC37X_VCU_CAN12, VcuCan12TxMsg2_oTC37X_VCU_CAN12]
package /PDU
  dcm i pdu MasterReq_ERV_oLIN00: length=8, diag-pdu-type=DIAG-REQUEST
  dcm i pdu MasterReq_EXV_1_oLIN00: length=8, diag-pdu-type=DIAG-REQUEST
  dcm i pdu MasterReq_EXV_2_oLIN00: length=8, diag-pdu-type=DIAG-REQUEST
  dcm i pdu MasterReq_GWM_oLIN01: length=8, diag-pdu-type=DIAG-REQUEST
  dcm i pdu MasterReq_GWM_oLIN02: length=8, diag-pdu-type=DIAG-REQUEST
  dcm i pdu MasterReq_HVCH_oLIN00: length=8, diag-pdu-type=DIAG-REQUEST
  dcm i pdu MasterReq_oLIN{00..02}: length=8, diag-pdu-type=DIAG-REQUEST
  dcm i pdu MasterReq_PMP_1_oLIN00: length=8, diag-pdu-type=DIAG-REQUEST
  dcm i pdu MasterReq_PMP_2_oLIN00: length=8, diag-pdu-type=DIAG-REQUEST
  dcm i pdu MasterReq_SVA_oLIN00: length=8, diag-pdu-type=DIAG-REQUEST
  dcm i pdu SlaveResp_ERV_oLIN00: length=8, diag-pdu-type=DIAG-RESPONSE
  dcm i pdu SlaveResp_EXV_1_oLIN00: length=8, diag-pdu-type=DIAG-RESPONSE
  dcm i pdu SlaveResp_EXV_2_oLIN00: length=8, diag-pdu-type=DIAG-RESPONSE
  dcm i pdu SlaveResp_GWM_oLIN01: length=8, diag-pdu-type=DIAG-RESPONSE
  dcm i pdu SlaveResp_GWM_oLIN02: length=8, diag-pdu-type=DIAG-RESPONSE
  dcm i pdu SlaveResp_HVCH_oLIN00: length=8, diag-pdu-type=DIAG-RESPONSE
  dcm i pdu SlaveResp_PMP_1_oLIN00: length=8, diag-pdu-type=DIAG-RESPONSE
  dcm i pdu SlaveResp_PMP_2_oLIN00: length=8, diag-pdu-type=DIAG-RESPONSE
  dcm i pdu SlaveResp_SVA_oLIN00: length=8, diag-pdu-type=DIAG-RESPONSE
  dcm i pdu Vcu_Uds_Func_Request_oTC37X_VCU_CAN00: length=7, diag-pdu-type=DIAG-REQUEST
  dcm i pdu Vcu_Uds_Phy_Request_oTC37X_VCU_CAN00: length=8, diag-pdu-type=DIAG-REQUEST
  dcm i pdu Vcu_Uds_Response_oTC37X_VCU_CAN00: length=8, diag-pdu-type=DIAG-RESPONSE
package /ISignal
  31 x i signal group:
    SG_ACU_01_SigGroup_oACU_01_oATOM_CANFD_Matrix_CH_V600_202502: i-signal=[ACU_YawRate_oACU_01_oATOM_CANFD_Matrix_CH_V600_202502, ACU_YawRateStatus_oACU_01_oATOM_CANFD_Matrix_CH_V600_202502, Checksum_0F5_oACU_01_oATOM_CANFD_Matrix_CH_V600_202502, MessageCounter_0F5_oACU_01_oATOM_CANFD_Matrix_CH_V600_202502], system-signal-group=SG_ACU_01_SigGroup
    SG_ACU_02_SigGroup_oACU_02_oATOM_CANFD_Matrix_CH_V600_202502: i-signal=[ACU_LatA_oACU_02_oATOM_CANFD_Matrix_CH_V600_202502, ACU_LatAStatus_oACU_02_oATOM_CANFD_Matrix_CH_V600_202502, ACU_LgtA_oACU_02_oATOM_CANFD_Matrix_CH_V600_202502, ACU_LgtAStatus_oACU_02_oATOM_CANFD_Matrix_CH_V600_202502, Checksum_0F6_oACU_02_oATOM_CANFD_Matrix_CH_V600_202502, MessageCounter_0F6_oACU_02_oATOM_CANFD_Matrix_CH_V600_202502], system-signal-group=SG_ACU_02_SigGroup
    SG_ACU_info_SigGroup_oACU_info_oATOM_CANFD_Matrix_CH_V600_202502: i-signal=[ACU_CrashOutputSts_oACU_info_oATOM_CANFD_Matrix_CH_V600_202502, ACU_CrashOutputStsValid_oACU_info_oATOM_CANFD_Matrix_CH_V600_202502, ACU_DriverSeatBeltSts_oACU_info_oATOM_CANFD_Matrix_CH_V600_202502, ACU_DriverSeatBeltStsValid_oACU_info_oATOM_CANFD_Matrix_CH_V600_202502, ACU_DriverWarningLampSts_oACU_info_oATOM_CANFD_Matrix_CH_V600_202502, ACU_PassengerAirbagSts_oACU_info_oATOM_CANFD_Matrix_CH_V600_202502, ACU_PassengerSeatBeltSts_oACU_info_oATOM_CANFD_Matrix_CH_V600_202502, ACU_PassengerSeatBeltStsValid_oACU_info_oATOM_CANFD_Matrix_CH_V600_202502, ACU_PassengerSts_oACU_info_oATOM_CANFD_Matrix_CH_V600_202502, ACU_PassengerWarningLampSts_oACU_info_oATOM_CANFD_Matrix_CH_V600_202502, ACU_RLSeatBeltStatusValid_oACU_info_oATOM_CANFD_Matrix_CH_V600_202502, ACU_RRSeatBeltStatusValid_oACU_info_oATOM_CANFD_Matrix_CH_V600_202502, ACU_SecondLeftSeatBeltSts_oACU_info_oATOM_CANFD_Matrix_CH_V600_202502, ACU_SecondLeftSts_oACU_info_oATOM_CANFD_Matrix_CH_V600_202502, ACU_SecondRightSeatBeltSts_oACU_info_oATOM_CANFD_Matrix_CH_V600_202502, ACU_SecondRightSts_oACU_info_oATOM_CANFD_Matrix_CH_V600_202502, ACU_WarningLampSts_oACU_info_oATOM_CANFD_Matrix_CH_V600_202502, Checksum_097_oACU_info_oATOM_CANFD_Matrix_CH_V600_202502, MessageCounter_097_oACU_info_oATOM_CANFD_Matrix_CH_V600_202502], system-signal-group=SG_ACU_info_SigGroup
    SG_ADCU_ACC_02_SigGroup_oADCU_ACC_02_oATOM_CANFD_Matrix_CH_V600_202502: i-signal=[ADCU_ACC_Mode_oADCU_ACC_02_oATOM_CANFD_Matrix_CH_V600_202502, ADCU_ACCDA_HandsOFF_Warning_oADCU_ACC_02_oATOM_CANFD_Matrix_CH_V600_202502, ADCU_ACCDA_SYS_Failure_oADCU_ACC_02_oATOM_CANFD_Matrix_CH_V600_202502, Checksum_0E0_oADCU_ACC_02_oATOM_CANFD_Matrix_CH_V600_202502, MessageCounter_0E0_oADCU_ACC_02_oATOM_CANFD_Matrix_CH_V600_202502], system-signal-group=SG_ADCU_ACC_02_SigGroup
    SG_ADCU_AEB_01_SigGroup_oADCU_AEB_01_oATOM_CANFD_Matrix_CH_V600_202502: i-signal=[ADCU_AEB_AWB_Level_oADCU_AEB_01_oATOM_CANFD_Matrix_CH_V600_202502, ADCU_AEB_AWB_Req_oADCU_AEB_01_oATOM_CANFD_Matrix_CH_V600_202502, ADCU_AEB_Decel_Cmd_oADCU_AEB_01_oATOM_CANFD_Matrix_CH_V600_202502, ADCU_AEB_Prefill_CMD_oADCU_AEB_01_oATOM_CANFD_Matrix_CH_V600_202502, ADCU_AEB_State_oADCU_AEB_01_oATOM_CANFD_Matrix_CH_V600_202502, ADCU_AEB_Stop_Req_oADCU_AEB_01_oATOM_CANFD_Matrix_CH_V600_202502, ADCU_AEBReq_oADCU_AEB_01_oATOM_CANFD_Matrix_CH_V600_202502, ADCU_AEBWarningSts_oADCU_AEB_01_oATOM_CANFD_Matrix_CH_V600_202502, ADCU_FCW_State_oADCU_AEB_01_oATOM_CANFD_Matrix_CH_V600_202502, Checksum_0E2_oADCU_AEB_01_oATOM_CANFD_Matrix_CH_V600_202502, MessageCounter_0E2_oADCU_AEB_01_oATOM_CANFD_Matrix_CH_V600_202502], system-signal-group=SG_ADCU_AEB_01_SigGroup
    SG_ADCU_APS_01_SigGroup_oADCU_APS_01_oATOM_CANFD_Matrix_CH_V600_202502: i-signal=[ADCU_APS_Stop_Req_oADCU_APS_01_oATOM_CANFD_Matrix_CH_V600_202502, ADCU_APSComfBrkReq_oADCU_APS_01_oATOM_CANFD_Matrix_CH_V600_202502, ADCU_APSCrlModeReq_oADCU_APS_01_oATOM_CANFD_Matrix_CH_V600_202502, ADCU_APSCrlReq_oADCU_APS_01_oATOM_CANFD_Matrix_CH_V600_202502, ADCU_APSCrlTypReq_oADCU_APS_01_oATOM_CANFD_Matrix_CH_V600_202502, ADCU_APSDistanceStop_oADCU_APS_01_oATOM_CANFD_Matrix_CH_V600_202502, ADCU_APSMaxSpeedReq_oADCU_APS_01_oATOM_CANFD_Matrix_CH_V600_202502, ADCU_Parking_CtrlSts_oADCU_APS_01_oATOM_CANFD_Matrix_CH_V600_202502, ADCU_Parking_Mode_oADCU_APS_01_oATOM_CANFD_Matrix_CH_V600_202502, ADCU_TargetGear_oADCU_APS_01_oATOM_CANFD_Matrix_CH_V600_202502, Checksum_0E4_oADCU_APS_01_oATOM_CANFD_Matrix_CH_V600_202502, MessageCounter_0E4_oADCU_APS_01_oATOM_CANFD_Matrix_CH_V600_202502], system-signal-group=SG_ADCU_APS_01_SigGroup
    SG_ADCU_APS_02_SigGroup_oADCU_APS_02_oATOM_CANFD_Matrix_CH_V600_202502: i-signal=ADCU_RemoteParkingMode_oADCU_APS_02_oATOM_CANFD_Matrix_CH_V600_202502, system-signal-group=SG_ADCU_APS_02_SigGroup
    SG_ADCU_DA_SigGroup_oADCU_DA_oATOM_CANFD_Matrix_CH_V600_202502: i-signal=[ADCU_DA_Mode_oADCU_DA_oATOM_CANFD_Matrix_CH_V600_202502, Checksum_0E6_oADCU_DA_oATOM_CANFD_Matrix_CH_V600_202502, MessageCounter_0E6_oADCU_DA_oATOM_CANFD_Matrix_CH_V600_202502], system-signal-group=SG_ADCU_DA_SigGroup
    SG_IBS_ACC_SigGroup_oIBS_ACC_oATOM_CANFD_Matrix_CH_V600_202502: i-signal=[Checksum_0B8_oIBS_ACC_oATOM_CANFD_Matrix_CH_V600_202502, IBS_CddActive_oIBS_ACC_oATOM_CANFD_Matrix_CH_V600_202502, IBS_CddAvailable_oIBS_ACC_oATOM_CANFD_Matrix_CH_V600_202502, IBS_CddError_oIBS_ACC_oATOM_CANFD_Matrix_CH_V600_202502, IBS_VehicleStandstill_oIBS_ACC_oATOM_CANFD_Matrix_CH_V600_202502, IBS_VehicleStandstill_Valid_oIBS_ACC_oATOM_CANFD_Matrix_CH_V600_202502, IBS_VlcActive_oIBS_ACC_oATOM_CANFD_Matrix_CH_V600_202502, IBS_VlcAvalible_oIBS_ACC_oATOM_CANFD_Matrix_CH_V600_202502, IBS_VlcError_oIBS_ACC_oATOM_CANFD_Matrix_CH_V600_202502, IBS_WLTorqueVLCReq_oIBS_ACC_oATOM_CANFD_Matrix_CH_V600_202502, IBS_WLTorqueVLCReqValid_oIBS_ACC_oATOM_CANFD_Matrix_CH_V600_202502, MessageCounter_0B8_oIBS_ACC_oATOM_CANFD_Matrix_CH_V600_202502], system-signal-group=SG_IBS_ACC_SigGroup
    SG_IBS_APS_SigGroup_oIBS_APS_oATOM_CANFD_Matrix_CH_V600_202502: i-signal=[Checksum_0B7_oIBS_APS_oATOM_CANFD_Matrix_CH_V600_202502, IBS_APS_Avl_oIBS_APS_oATOM_CANFD_Matrix_CH_V600_202502, IBS_APSComfortAvl_oIBS_APS_oATOM_CANFD_Matrix_CH_V600_202502, IBS_APSCrlReqEcho_oIBS_APS_oATOM_CANFD_Matrix_CH_V600_202502, IBS_APSEmergenyAvl_oIBS_APS_oATOM_CANFD_Matrix_CH_V600_202502, IBS_APSModeEcho_oIBS_APS_oATOM_CANFD_Matrix_CH_V600_202502, IBS_APSTrqReqActive_oIBS_APS_oATOM_CANFD_Matrix_CH_V600_202502, IBS_BrakeTypEcho_oIBS_APS_oATOM_CANFD_Matrix_CH_V600_202502, MessageCounter_0B7_oIBS_APS_oATOM_CANFD_Matrix_CH_V600_202502], system-signal-group=SG_IBS_APS_SigGroup
    SG_IBS_Status_01_SigGroup_oIBS_Status_01_oATOM_CANFD_Matrix_CH_V600_202502: i-signal=[Checksum_0B2_oIBS_Status_01_oATOM_CANFD_Matrix_CH_V600_202502, IBS_BrakePedalStatus_oIBS_Status_01_oATOM_CANFD_Matrix_CH_V600_202502, IBS_BrakePedalStatusValid_oIBS_Status_01_oATOM_CANFD_Matrix_CH_V600_202502, IBS_BrakePushrodStroke_oIBS_Status_01_oATOM_CANFD_Matrix_CH_V600_202502, IBS_MasterCylinderPressure_oIBS_Status_01_oATOM_CANFD_Matrix_CH_V600_202502, IBS_PlungerPressure_oIBS_Status_01_oATOM_CANFD_Matrix_CH_V600_202502, MessageCounter_0B2_oIBS_Status_01_oATOM_CANFD_Matrix_CH_V600_202502], system-signal-group=SG_IBS_Status_01_SigGroup
    SG_IBS_Status_02_SigGroup_oIBS_Status_02_oATOM_CANFD_Matrix_CH_V600_202502: i-signal=[Checksum_0B3_oIBS_Status_02_oATOM_CANFD_Matrix_CH_V600_202502, IBS_AEBActive_oIBS_Status_02_oATOM_CANFD_Matrix_CH_V600_202502, IBS_AEBAvailable_oIBS_Status_02_oATOM_CANFD_Matrix_CH_V600_202502, IBS_AVHAvailable_oIBS_Status_02_oATOM_CANFD_Matrix_CH_V600_202502, IBS_AWBActive_oIBS_Status_02_oATOM_CANFD_Matrix_CH_V600_202502, IBS_AWBAvailable_oIBS_Status_02_oATOM_CANFD_Matrix_CH_V600_202502, IBS_BrakeLightRequest_oIBS_Status_02_oATOM_CANFD_Matrix_CH_V600_202502, IBS_EPBControllerSts_oIBS_Status_02_oATOM_CANFD_Matrix_CH_V600_202502, IBS_EPBFailureLamp_oIBS_Status_02_oATOM_CANFD_Matrix_CH_V600_202502, IBS_EPBFunctionLamp_oIBS_Status_02_oATOM_CANFD_Matrix_CH_V600_202502, IBS_EPBworkingSts_oIBS_Status_02_oATOM_CANFD_Matrix_CH_V600_202502, IBS_HazWarnReq_oIBS_Status_02_oATOM_CANFD_Matrix_CH_V600_202502, IBS_HDCAvailable_oIBS_Status_02_oATOM_CANFD_Matrix_CH_V600_202502, IBS_HHCActive_oIBS_Status_02_oATOM_CANFD_Matrix_CH_V600_202502, IBS_HHCAvailable_oIBS_Status_02_oATOM_CANFD_Matrix_CH_V600_202502, IBS_TCSActive_oIBS_Status_02_oATOM_CANFD_Matrix_CH_V600_202502, IBS_VDCActive_oIBS_Status_02_oATOM_CANFD_Matrix_CH_V600_202502, MessageCounter_0B3_oIBS_Status_02_oATOM_CANFD_Matrix_CH_V600_202502], system-signal-group=SG_IBS_Status_02_SigGroup
    SG_IBS_Status_03_SigGroup_oIBS_Status_03_oATOM_CANFD_Matrix_CH_V600_202502: i-signal=[Checksum_0B4_oIBS_Status_03_oATOM_CANFD_Matrix_CH_V600_202502, IBS_ABPActive_oIBS_Status_03_oATOM_CANFD_Matrix_CH_V600_202502, IBS_ABPAvailable_oIBS_Status_03_oATOM_CANFD_Matrix_CH_V600_202502, IBS_ABSActive_oIBS_Status_03_oATOM_CANFD_Matrix_CH_V600_202502, IBS_ABSFault_oIBS_Status_03_oATOM_CANFD_Matrix_CH_V600_202502, IBS_DTCFault_oIBS_Status_03_oATOM_CANFD_Matrix_CH_V600_202502, IBS_EBDActive_oIBS_Status_03_oATOM_CANFD_Matrix_CH_V600_202502, IBS_EBDFault_oIBS_Status_03_oATOM_CANFD_Matrix_CH_V600_202502, IBS_EPBTextdisplay_oIBS_Status_03_oATOM_CANFD_Matrix_CH_V600_202502, IBS_SystemStatus_oIBS_Status_03_oATOM_CANFD_Matrix_CH_V600_202502, IBS_TCSFault_oIBS_Status_03_oATOM_CANFD_Matrix_CH_V600_202502, IBS_VCU_DecelerationRequest_Available_oIBS_Status_03_oATOM_CANFD_Matrix_CH_V600_202502, IBS_VDCFault_oIBS_Status_03_oATOM_CANFD_Matrix_CH_V600_202502, IBS_VehicleSpeed_oIBS_Status_03_oATOM_CANFD_Matrix_CH_V600_202502, IBS_VehicleSpeedValid_oIBS_Status_03_oATOM_CANFD_Matrix_CH_V600_202502, MessageCounter_0B4_oIBS_Status_03_oATOM_CANFD_Matrix_CH_V600_202502], system-signal-group=SG_IBS_Status_03_SigGroup
    SG_IBS_Status_04_SigGroup_oIBS_Status_04_oATOM_CANFD_Matrix_CH_V600_202502: i-signal=[Checksum_0BA_oIBS_Status_04_oATOM_CANFD_Matrix_CH_V600_202502, IBS_CDPActive_oIBS_Status_04_oATOM_CANFD_Matrix_CH_V600_202502, IBS_CDPAvailable_oIBS_Status_04_oATOM_CANFD_Matrix_CH_V600_202502, IBS_DTCActive_oIBS_Status_04_oATOM_CANFD_Matrix_CH_V600_202502, MessageCounter_0BA_oIBS_Status_04_oATOM_CANFD_Matrix_CH_V600_202502], system-signal-group=SG_IBS_Status_04_SigGroup
    SG_IBS_Status_06_SigGroup_oIBS_Status_06_oATOM_CANFD_Matrix_CH_V600_202502: i-signal=[Checksum_0BC_oIBS_Status_06_oATOM_CANFD_Matrix_CH_V600_202502, IBS_AVHSts_oIBS_Status_06_oATOM_CANFD_Matrix_CH_V600_202502, IBS_BrakeFluidWarning_oIBS_Status_06_oATOM_CANFD_Matrix_CH_V600_202502, IBS_EPBFailureStatus_oIBS_Status_06_oATOM_CANFD_Matrix_CH_V600_202502, IBS_ESClampdisplay_oIBS_Status_06_oATOM_CANFD_Matrix_CH_V600_202502, IBS_ESCOffSts_oIBS_Status_06_oATOM_CANFD_Matrix_CH_V600_202502, IBS_FactoryMode_oIBS_Status_06_oATOM_CANFD_Matrix_CH_V600_202502, IBS_HBAActive_oIBS_Status_06_oATOM_CANFD_Matrix_CH_V600_202502, IBS_HDCSts_oIBS_Status_06_oATOM_CANFD_Matrix_CH_V600_202502, IBS_MaintenaceMode_oIBS_Status_06_oATOM_CANFD_Matrix_CH_V600_202502, IBS_RollerbenchMode_oIBS_Status_06_oATOM_CANFD_Matrix_CH_V600_202502, IBS_RWUActive_oIBS_Status_06_oATOM_CANFD_Matrix_CH_V600_202502, IBS_RWUAvailable_oIBS_Status_06_oATOM_CANFD_Matrix_CH_V600_202502, IBS_TireMonSysSts_oIBS_Status_06_oATOM_CANFD_Matrix_CH_V600_202502, IBS_TireWarnFrntLe_oIBS_Status_06_oATOM_CANFD_Matrix_CH_V600_202502, IBS_TireWarnFrntRi_oIBS_Status_06_oATOM_CANFD_Matrix_CH_V600_202502, IBS_TireWarnReLe_oIBS_Status_06_oATOM_CANFD_Matrix_CH_V600_202502, IBS_TireWarnReRi_oIBS_Status_06_oATOM_CANFD_Matrix_CH_V600_202502, IBS_TPMS_ResetSts_oIBS_Status_06_oATOM_CANFD_Matrix_CH_V600_202502, MessageCounter_0BC_oIBS_Status_06_oATOM_CANFD_Matrix_CH_V600_202502], system-signal-group=SG_IBS_Status_06_SigGroup
    SG_IBS_Torque_SigGroup_oIBS_Torque_oATOM_CANFD_Matrix_CH_V600_202502: i-signal=[Checksum_0B9_oIBS_Torque_oATOM_CANFD_Matrix_CH_V600_202502, IBS_RBSStatus_oIBS_Torque_oATOM_CANFD_Matrix_CH_V600_202502, IBS_TargetGearReq_oIBS_Torque_oATOM_CANFD_Matrix_CH_V600_202502, IBS_VCU_DecelerationReqActive_oIBS_Torque_oATOM_CANFD_Matrix_CH_V600_202502, IBS_WLTorqueAPSReq_oIBS_Torque_oATOM_CANFD_Matrix_CH_V600_202502, IBS_WLTorqueAPSReqValid_oIBS_Torque_oATOM_CANFD_Matrix_CH_V600_202502, IBS_WLTorqueRBSReq_oIBS_Torque_oATOM_CANFD_Matrix_CH_V600_202502, IBS_WLTorqueRBSReqValid_oIBS_Torque_oATOM_CANFD_Matrix_CH_V600_202502, MessageCounter_0B9_oIBS_Torque_oATOM_CANFD_Matrix_CH_V600_202502], system-signal-group=SG_IBS_Torque_SigGroup
    SG_IBS_VCU_MotorControl_SigGroup_oIBS_VCU_MotorControl_oATOM_CANFD_Matrix_CH_V600_202502: i-signal=[Checksum_090_oIBS_VCU_MotorControl_oATOM_CANFD_Matrix_CH_V600_202502, IBS_WLTorqueIncrReq_oIBS_VCU_MotorControl_oATOM_CANFD_Matrix_CH_V600_202502, IBS_WLTorqueIncrReqSts_oIBS_VCU_MotorControl_oATOM_CANFD_Matrix_CH_V600_202502, IBS_WLTorqueRedReq_oIBS_VCU_MotorControl_oATOM_CANFD_Matrix_CH_V600_202502, IBS_WLTorqueRedReqSts_oIBS_VCU_MotorControl_oATOM_CANFD_Matrix_CH_V600_202502, MessageCounter_090_oIBS_VCU_MotorControl_oATOM_CANFD_Matrix_CH_V600_202502], system-signal-group=SG_IBS_VCU_MotorControl_SigGroup
    SG_IBS_WheelSpeed_01_SigGroup_oIBS_WheelSpeed_01_oATOM_CANFD_Matrix_CH_V600_202502: i-signal=[Checksum_0B0_oIBS_WheelSpeed_01_oATOM_CANFD_Matrix_CH_V600_202502, IBS_FLMovingDirection_oIBS_WheelSpeed_01_oATOM_CANFD_Matrix_CH_V600_202502, IBS_FLWheelPulseCounter_oIBS_WheelSpeed_01_oATOM_CANFD_Matrix_CH_V600_202502, IBS_FLWheelSpeed_oIBS_WheelSpeed_01_oATOM_CANFD_Matrix_CH_V600_202502, IBS_FLWheelSpeed_Fault_oIBS_WheelSpeed_01_oATOM_CANFD_Matrix_CH_V600_202502, IBS_FRMovingDirection_oIBS_WheelSpeed_01_oATOM_CANFD_Matrix_CH_V600_202502, IBS_FRWheelPulseCounter_oIBS_WheelSpeed_01_oATOM_CANFD_Matrix_CH_V600_202502, IBS_FRWheelSpeed_oIBS_WheelSpeed_01_oATOM_CANFD_Matrix_CH_V600_202502, IBS_FRWheelSpeed_Fault_oIBS_WheelSpeed_01_oATOM_CANFD_Matrix_CH_V600_202502, MessageCounter_0B0_oIBS_WheelSpeed_01_oATOM_CANFD_Matrix_CH_V600_202502], system-signal-group=SG_IBS_WheelSpeed_01_SigGroup
    SG_IBS_WheelSpeed_02_SigGroup_oIBS_WheelSpeed_02_oATOM_CANFD_Matrix_CH_V600_202502: i-signal=[Checksum_0B1_oIBS_WheelSpeed_02_oATOM_CANFD_Matrix_CH_V600_202502, IBS_RLMovingDirection_oIBS_WheelSpeed_02_oATOM_CANFD_Matrix_CH_V600_202502, IBS_RLWheelPulseCounter_oIBS_WheelSpeed_02_oATOM_CANFD_Matrix_CH_V600_202502, IBS_RLWheelSpeed_oIBS_WheelSpeed_02_oATOM_CANFD_Matrix_CH_V600_202502, IBS_RLWheelSpeed_Fault_oIBS_WheelSpeed_02_oATOM_CANFD_Matrix_CH_V600_202502, IBS_RRMovingDirection_oIBS_WheelSpeed_02_oATOM_CANFD_Matrix_CH_V600_202502, IBS_RRWheelPulseCounter_oIBS_WheelSpeed_02_oATOM_CANFD_Matrix_CH_V600_202502, IBS_RRWheelSpeed_oIBS_WheelSpeed_02_oATOM_CANFD_Matrix_CH_V600_202502, IBS_RRWheelSpeed_Fault_oIBS_WheelSpeed_02_oATOM_CANFD_Matrix_CH_V600_202502, MessageCounter_0B1_oIBS_WheelSpeed_02_oATOM_CANFD_Matrix_CH_V600_202502], system-signal-group=SG_IBS_WheelSpeed_02_SigGroup
    SG_SGW_17_SigGroup_oSGW_17_oATOM_CANFD_Matrix_CH_V600_202502: i-signal=SGW_BLESystemReadyReq_oSGW_17_oATOM_CANFD_Matrix_CH_V600_202502, system-signal-group=SG_SGW_17_SigGroup
    SG_VCU_02_SigGroup_oVCU_02_oATOM_CANFD_Matrix_CH_V600_202502: i-signal=[VCU_BS_Current_oVCU_02_oATOM_CANFD_Matrix_CH_V600_202502, VCU_BS_IBSBatSOC_oVCU_02_oATOM_CANFD_Matrix_CH_V600_202502, VCU_BS_IndicatorSts_oVCU_02_oATOM_CANFD_Matrix_CH_V600_202502, VCU_BS_LV_Batt_oVCU_02_oATOM_CANFD_Matrix_CH_V600_202502, VCU_WakeUpStatus_oVCU_02_oATOM_CANFD_Matrix_CH_V600_202502], system-signal-group=SG_VCU_02_SigGroup
    SG_VCU_03_SigGroup_oVCU_03_oATOM_CANFD_Matrix_CH_V600_202502: i-signal=[VCU_BrakeCompensateStatus_oVCU_03_oATOM_CANFD_Matrix_CH_V600_202502, VCU_ChargeProcessComment_oVCU_03_oATOM_CANFD_Matrix_CH_V600_202502, VCU_DCFCCurrent_oVCU_03_oATOM_CANFD_Matrix_CH_V600_202502, VCU_EnergyV2L_oVCU_03_oATOM_CANFD_Matrix_CH_V600_202502, VCU_MemoryChargeFault_oVCU_03_oATOM_CANFD_Matrix_CH_V600_202502], system-signal-group=SG_VCU_03_SigGroup
    SG_VCU_04_SigGroup_oVCU_04_oATOM_CANFD_Matrix_CH_V600_202502: i-signal=[VCU_ForwardVmaxlimitStatus_oVCU_04_oATOM_CANFD_Matrix_CH_V600_202502, VCU_ManuallyUnlockComment_oVCU_04_oATOM_CANFD_Matrix_CH_V600_202502], system-signal-group=SG_VCU_04_SigGroup
    SG_VCU_AccPedal_SigGroup_oVCU_AccPedal_oATOM_CANFD_Matrix_CH_V600_202502: i-signal=[Checksum_0D2_oVCU_AccPedal_oATOM_CANFD_Matrix_CH_V600_202502, MessageCounter_0D2_oVCU_AccPedal_oATOM_CANFD_Matrix_CH_V600_202502, VCU_AccelerationPedal_oVCU_AccPedal_oATOM_CANFD_Matrix_CH_V600_202502, VCU_AccelerationPedalValid_oVCU_AccPedal_oATOM_CANFD_Matrix_CH_V600_202502, VCU_EPBReq_oVCU_AccPedal_oATOM_CANFD_Matrix_CH_V600_202502, VCU_Kickdown_oVCU_AccPedal_oATOM_CANFD_Matrix_CH_V600_202502, VCU_TargetGear_oVCU_AccPedal_oATOM_CANFD_Matrix_CH_V600_202502, VCU_VehicleSpeed_oVCU_AccPedal_oATOM_CANFD_Matrix_CH_V600_202502, VCU_VehicleSpeedValid_oVCU_AccPedal_oATOM_CANFD_Matrix_CH_V600_202502, VCU_VirtualACPedal_oVCU_AccPedal_oATOM_CANFD_Matrix_CH_V600_202502, VCU_VirtualACPedalValid_oVCU_AccPedal_oATOM_CANFD_Matrix_CH_V600_202502, VCU_VLCTorqueRequestActive_oVCU_AccPedal_oATOM_CANFD_Matrix_CH_V600_202502, VCU_VLCTorqueRequestAvailable_oVCU_AccPedal_oATOM_CANFD_Matrix_CH_V600_202502], system-signal-group=SG_VCU_AccPedal_SigGroup
    SG_VCU_BMS_SigGroup_oVCU_BMS_oATOM_CANFD_Matrix_CH_V600_202502: i-signal=[Checksum_0D1_oVCU_BMS_oATOM_CANFD_Matrix_CH_V600_202502, MessageCounter_0D1_oVCU_BMS_oATOM_CANFD_Matrix_CH_V600_202502, VCU_ActDriveMode_oVCU_BMS_oATOM_CANFD_Matrix_CH_V600_202502, VCU_BMS_Control_of_PosRelay_oVCU_BMS_oATOM_CANFD_Matrix_CH_V600_202502, VCU_BMSTargetThermLevel_oVCU_BMS_oATOM_CANFD_Matrix_CH_V600_202502, VCU_ChargeStatus_oVCU_BMS_oATOM_CANFD_Matrix_CH_V600_202502, VCU_DrvModSwitchWarn_oVCU_BMS_oATOM_CANFD_Matrix_CH_V600_202502, VCU_HVStatus_oVCU_BMS_oATOM_CANFD_Matrix_CH_V600_202502, VCU_IsoMeasurementSwitch_oVCU_BMS_oATOM_CANFD_Matrix_CH_V600_202502, VCU_LimitLevel_oVCU_BMS_oATOM_CANFD_Matrix_CH_V600_202502, VCU_RegenBrakeLightRequest_oVCU_BMS_oATOM_CANFD_Matrix_CH_V600_202502, VCU_RegenBrakeLightReqVld_oVCU_BMS_oATOM_CANFD_Matrix_CH_V600_202502, VCU_RequestedModeBMS_oVCU_BMS_oATOM_CANFD_Matrix_CH_V600_202502], system-signal-group=SG_VCU_BMS_SigGroup
    SG_VCU_Chassis_01_SigGroup_oVCU_Chassis_01_oATOM_CANFD_Matrix_CH_V600_202502: i-signal=[Checksum_0D3_oVCU_Chassis_01_oATOM_CANFD_Matrix_CH_V600_202502, MessageCounter_0D3_oVCU_Chassis_01_oATOM_CANFD_Matrix_CH_V600_202502, VCU_ADASOverride_oVCU_Chassis_01_oATOM_CANFD_Matrix_CH_V600_202502, VCU_APSTorqueRequestActive_oVCU_Chassis_01_oATOM_CANFD_Matrix_CH_V600_202502, VCU_APSTorqueRequestAvailable_oVCU_Chassis_01_oATOM_CANFD_Matrix_CH_V600_202502, VCU_BrakeCompensateWarn_oVCU_Chassis_01_oATOM_CANFD_Matrix_CH_V600_202502, VCU_DecelerationReq_oVCU_Chassis_01_oATOM_CANFD_Matrix_CH_V600_202502, VCU_DecelerationReqactive_oVCU_Chassis_01_oATOM_CANFD_Matrix_CH_V600_202502, VCU_DriverTorqueRequest_oVCU_Chassis_01_oATOM_CANFD_Matrix_CH_V600_202502, VCU_EnergyManagementWarn_oVCU_Chassis_01_oATOM_CANFD_Matrix_CH_V600_202502, VCU_RegenTorqueCap_oVCU_Chassis_01_oATOM_CANFD_Matrix_CH_V600_202502, VCU_RegenTorqueCapValid_oVCU_Chassis_01_oATOM_CANFD_Matrix_CH_V600_202502, VCU_RegStatus_oVCU_Chassis_01_oATOM_CANFD_Matrix_CH_V600_202502, VCU_TorqueRequestActive_oVCU_Chassis_01_oATOM_CANFD_Matrix_CH_V600_202502, VCU_TorqueRequestAvailable_oVCU_Chassis_01_oATOM_CANFD_Matrix_CH_V600_202502], system-signal-group=SG_VCU_Chassis_01_SigGroup
    SG_VCU_HMIsignals_01_SigGroup_oVCU_HMIsignals_01_oATOM_CANFD_Matrix_CH_V600_202502: i-signal=[Checksum_317_oVCU_HMIsignals_01_oATOM_CANFD_Matrix_CH_V600_202502, MessageCounter_317_oVCU_HMIsignals_01_oATOM_CANFD_Matrix_CH_V600_202502, VCU_CriSysFailure_oVCU_HMIsignals_01_oATOM_CANFD_Matrix_CH_V600_202502, VCU_DCDCFail_oVCU_HMIsignals_01_oATOM_CANFD_Matrix_CH_V600_202502, VCU_DriveMotOvrTemp_oVCU_HMIsignals_01_oATOM_CANFD_Matrix_CH_V600_202502, VCU_HVBatCriFail_oVCU_HMIsignals_01_oATOM_CANFD_Matrix_CH_V600_202502, VCU_HVBatOvrTemp_oVCU_HMIsignals_01_oATOM_CANFD_Matrix_CH_V600_202502, VCU_HVILError_oVCU_HMIsignals_01_oATOM_CANFD_Matrix_CH_V600_202502, VCU_HVInsulResFault_oVCU_HMIsignals_01_oATOM_CANFD_Matrix_CH_V600_202502, VCU_InvldGearSel_oVCU_HMIsignals_01_oATOM_CANFD_Matrix_CH_V600_202502, VCU_LimpHome_oVCU_HMIsignals_01_oATOM_CANFD_Matrix_CH_V600_202502, VCU_MileagelowRemind_oVCU_HMIsignals_01_oATOM_CANFD_Matrix_CH_V600_202502, VCU_PlugStatus_oVCU_HMIsignals_01_oATOM_CANFD_Matrix_CH_V600_202502, VCU_ReachLimitStd_oVCU_HMIsignals_01_oATOM_CANFD_Matrix_CH_V600_202502], system-signal-group=SG_VCU_HMIsignals_01_SigGroup
    SG_VCU_HMIsignals_02_SigGroup_oVCU_HMIsignals_02_oATOM_CANFD_Matrix_CH_V600_202502: i-signal=[Checksum_318_oVCU_HMIsignals_02_oATOM_CANFD_Matrix_CH_V600_202502, MessageCounter_318_oVCU_HMIsignals_02_oATOM_CANFD_Matrix_CH_V600_202502, VCU_DischargeEndSoc_oVCU_HMIsignals_02_oATOM_CANFD_Matrix_CH_V600_202502, VCU_Display_Cur_oVCU_HMIsignals_02_oATOM_CANFD_Matrix_CH_V600_202502, VCU_Display_Power_oVCU_HMIsignals_02_oATOM_CANFD_Matrix_CH_V600_202502, VCU_ForwardVmaxAllowed_oVCU_HMIsignals_02_oATOM_CANFD_Matrix_CH_V600_202502, VCU_maxChargeSOC_oVCU_HMIsignals_02_oATOM_CANFD_Matrix_CH_V600_202502, VCU_MCU_FaultLampReq_oVCU_HMIsignals_02_oATOM_CANFD_Matrix_CH_V600_202502, VCU_SystemReady_oVCU_HMIsignals_02_oATOM_CANFD_Matrix_CH_V600_202502], system-signal-group=SG_VCU_HMIsignals_02_SigGroup
    SG_VCU_IBS_01_SigGroup_oVCU_IBS_01_oATOM_CANFD_Matrix_CH_V600_202502: i-signal=[Checksum_094_oVCU_IBS_01_oATOM_CANFD_Matrix_CH_V600_202502, MessageCounter_094_oVCU_IBS_01_oATOM_CANFD_Matrix_CH_V600_202502, VCU_MotorActualTorque_oVCU_IBS_01_oATOM_CANFD_Matrix_CH_V600_202502, VCU_MotorActualTorqueValid_oVCU_IBS_01_oATOM_CANFD_Matrix_CH_V600_202502, VCU_OPStandstillReq_oVCU_IBS_01_oATOM_CANFD_Matrix_CH_V600_202502, VCU_WheelTrqACT_oVCU_IBS_01_oATOM_CANFD_Matrix_CH_V600_202502, VCU_WheelTrqACTValid_oVCU_IBS_01_oATOM_CANFD_Matrix_CH_V600_202502], system-signal-group=SG_VCU_IBS_01_SigGroup
    SG_VCU_MCU_03_SigGroup_oVCU_MCU_03_oATOM_CANFD_Matrix_CH_V600_202502: i-signal=[Checksum_095_oVCU_MCU_03_oATOM_CANFD_Matrix_CH_V600_202502, MessageCounter_095_oVCU_MCU_03_oATOM_CANFD_Matrix_CH_V600_202502, VCU_ActualGear_oVCU_MCU_03_oATOM_CANFD_Matrix_CH_V600_202502, VCU_BrakepedalStatus_oVCU_MCU_03_oATOM_CANFD_Matrix_CH_V600_202502, VCU_KL15eOn_oVCU_MCU_03_oATOM_CANFD_Matrix_CH_V600_202502, VCU_MCUDesiredTorque_oVCU_MCU_03_oATOM_CANFD_Matrix_CH_V600_202502, VCU_MCUSurgeDamperState_oVCU_MCU_03_oATOM_CANFD_Matrix_CH_V600_202502, VCU_PWTErrorLevel_oVCU_MCU_03_oATOM_CANFD_Matrix_CH_V600_202502, VCU_RequestedModeMCU_oVCU_MCU_03_oATOM_CANFD_Matrix_CH_V600_202502, VCU_TCSActive_oVCU_MCU_03_oATOM_CANFD_Matrix_CH_V600_202502, VCU_TrqThresholdDampgCtl_oVCU_MCU_03_oATOM_CANFD_Matrix_CH_V600_202502], system-signal-group=SG_VCU_MCU_03_SigGroup
    SG_VCU_PlugInChrgInfo_SigGroup_oVCU_PlugInChrgInfo_oATOM_CANFD_Matrix_CH_V600_202502: i-signal=[VCU_ChargeEndReason_oVCU_PlugInChrgInfo_oATOM_CANFD_Matrix_CH_V600_202502, VCU_DischargeEndReason_oVCU_PlugInChrgInfo_oATOM_CANFD_Matrix_CH_V600_202502, VCU_HVConnectFault_oVCU_PlugInChrgInfo_oATOM_CANFD_Matrix_CH_V600_202502, VCU_RemainChrgTime_oVCU_PlugInChrgInfo_oATOM_CANFD_Matrix_CH_V600_202502], system-signal-group=SG_VCU_PlugInChrgInfo_SigGroup
package /Signal
  4 x system signal:
    SGW_BLEChrgFlaplockCtrlReq: compu-method=CM_SGW_BLEChrgFlaplockCtrlReq, data-constr=DC_SGW_BLEChrgFlaplockCtrlReq  # Bluetooth key charging flap lock control command
    SGW_BLEPowerModeReq: compu-method=CM_SGW_BLEPowerModeReq, data-constr=DC_SGW_BLEPowerModeReq  # CBM request Power ON
    SGW_BLETailgateCtrlReq: compu-method=CM_SGW_BLETailgateCtrlReq, data-constr=DC_SGW_BLETailgateCtrlReq  # Bluetoot control back door command
    SGW_KeyLowBatWarning: compu-method=CM_SGW_KeyLowBatWarning, data-constr=DC_SGW_KeyLowBatWarning  # Fob battery low warning.
